VERSION ""

NS_ :

BS_:

BU_: FMS_Gateway
VAL_TABLE_ FMI 0 "Above normal (most severe)" 1 "Below normal (most severe)" 2 "Data erratic" 3 "Voltage above normal" 4 "Voltage below normal" 5 "Current below normal" 6 "Current above normal" 7 "Mechanical system not responding" 8 "Abnormal frequency" 9 "Abnormal update rate" 10 "Abnormal rate of change" 11 "Root cause not known" 12 "Bad intelligent device" 13 "Out of calibration" 14 "Special intstructions" 15 "Above normal (least severe)" 16 "Above normal (moderately severe)" 17 "Below normal (least severe)" 18 "Below normal (moderately severe)" 19 "Received network data in error" 20 "Data drifted high" 21 "Data drifted low" 31 "Condition exists" ;

BO_ 3221225472 VECTOR__INDEPENDENT_SIG_MSG: 0 Vector__XXX
 SG_ NetworkMessageControlByte : 0|8@1+ (1,0) [0|255] "" Vector__XXX

BO_ 2566827774 AIR1: 8 Vector__XXX
 SG_ ServiceBrakeAirPressureCircuit2 : 24|8@1+ (8,0) [0|2040] "kPa" Vector__XXX
 SG_ ServiceBrakeAirPressureCircuit1 : 16|8@1+ (8,0) [0|2040] "kPa" Vector__XXX

BO_ 2565868030 VDC2: 8 Vector__XXX
 SG_ SteeringWheelAngle : 0|16@1+ (0.0009765625,-31.374) [-31.374|31.374] "°" Vector__XXX

BO_ 2566699006 VEP4: 8 Vector__XXX
 SG_ HybridBatteryPackRemainingCharge : 0|16@1+ (0.0025,0) [0|163.6375] "" Vector__XXX

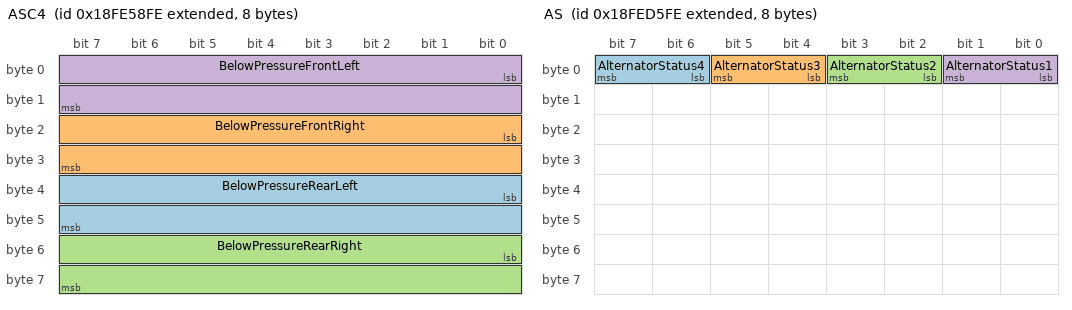
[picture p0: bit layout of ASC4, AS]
BO_ 2566805758 ASC4: 8 Vector__XXX
 SG_ BelowPressureRearLeft : 32|16@1+ (1,0) [0|0] "kPa" Vector__XXX
 SG_ BelowPressureFrontRight : 16|16@1+ (1,0) [0|0] "kPa" Vector__XXX
 SG_ BelowPressureRearRight : 48|16@1+ (1,0) [0|0] "kPa" Vector__XXX
 SG_ BelowPressureFrontLeft : 0|16@1+ (1,0) [0|0] "kPa" Vector__XXX

BO_ 2565867006 ETC2: 8 Vector__XXX
 SG_ SelectedGear : 0|8@1+ (1,-125) [-125|130] "" Vector__XXX
 SG_ CurrentGear : 24|8@1+ (1,-125) [-125|130] "" Vector__XXX

BO_ 2566837758 AS: 8 Vector__XXX
 SG_ AlternatorStatus4 : 6|2@1+ (1,0) [0|3] "" Vector__XXX
 SG_ AlternatorStatus3 : 4|2@1+ (1,0) [0|3] "" Vector__XXX
 SG_ AlternatorStatus2 : 2|2@1+ (1,0) [0|3] "" Vector__XXX
 SG_ AlternatorStatus1 : 0|2@1+ (1,0) [0|3] "" Vector__XXX

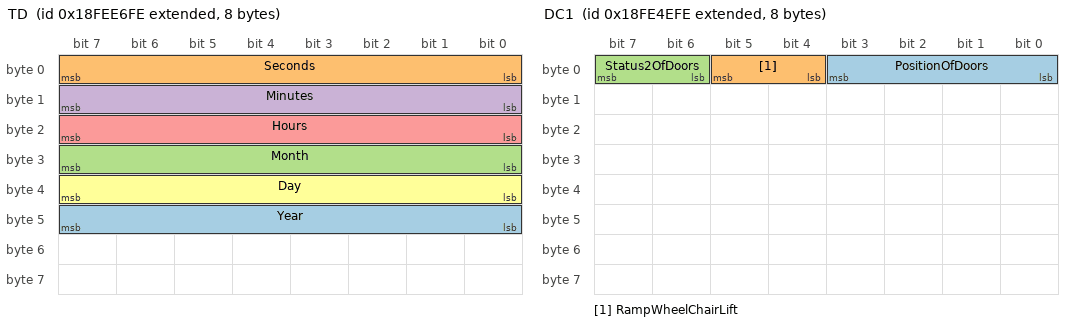
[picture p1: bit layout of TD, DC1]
BO_ 2566842110 TD: 8 Vector__XXX
 SG_ Year : 40|8@1+ (1,1985) [1985|2240] "" Vector__XXX
 SG_ Seconds : 0|8@1+ (0.25,0) [0|59.75] "s" Vector__XXX
 SG_ Month : 24|8@1+ (1,0) [0|11] "" Vector__XXX
 SG_ Minutes : 8|8@1- (1,0) [0|59] "min" Vector__XXX
 SG_ Hours : 16|8@1+ (1,0) [0|23] "" Vector__XXX
 SG_ Day : 32|8@1+ (0.25,0) [0|31] "d" Vector__XXX

BO_ 2566759934 DC2: 8 Vector__XXX
 SG_ EnableStatusDoor9 : 52|2@1+ (1,0) [0|3] "" Vector__XXX
 SG_ EnableStatusDoor8 : 46|2@1+ (1,0) [0|3] "" Vector__XXX
 SG_ EnableStatusDoor7 : 40|2@1+ (1,0) [0|3] "" Vector__XXX
 SG_ EnableStatusDoor6 : 34|2@1+ (1,0) [0|3] "" Vector__XXX
 SG_ EnableStatusDoor5 : 28|2@1+ (1,0) [0|3] "" Vector__XXX
 SG_ EnableStatusDoor4 : 22|2@1+ (1,0) [0|3] "" Vector__XXX
 SG_ EnableStatusDoor3 : 16|2@1+ (1,0) [0|3] "" Vector__XXX
 SG_ EnableStatusDoor2 : 10|2@1+ (1,0) [0|3] "" Vector__XXX
 SG_ EnableStatusDoor10 : 58|2@1+ (1,0) [0|3] "" Vector__XXX
 SG_ EnableStatusDoor1 : 4|2@1+ (1,0) [0|3] "" Vector__XXX
 SG_ OpenStatusDoor9 : 50|2@1+ (1,0) [0|3] "" Vector__XXX
 SG_ OpenStatusDoor8 : 44|2@1+ (1,0) [0|3] "" Vector__XXX
 SG_ OpenStatusDoor7 : 38|2@1+ (1,0) [0|3] "" Vector__XXX
 SG_ OpenStatusDoor6 : 32|2@1+ (1,0) [0|3] "" Vector__XXX
 SG_ OpenStatusDoor5 : 26|2@1+ (1,0) [0|3] "" Vector__XXX
 SG_ OpenStatusDoor4 : 20|2@1+ (1,0) [0|3] "" Vector__XXX
 SG_ OpenStatusDoor3 : 14|2@1+ (1,0) [0|3] "" Vector__XXX
 SG_ OpenStatusDoor2 : 8|2@1+ (1,0) [0|3] "" Vector__XXX
 SG_ OpenStatusDoor10 : 56|2@1+ (1,0) [0|3] "" Vector__XXX
 SG_ OpenStatusDoor1 : 2|2@1+ (1,0) [0|3] "" Vector__XXX
 SG_ LockStatusDoor9 : 48|2@1+ (1,0) [0|0] "" Vector__XXX
 SG_ LockStatusDoor8 : 42|2@1+ (1,0) [0|0] "" Vector__XXX
 SG_ LockStatusDoor7 : 36|2@1+ (1,0) [0|0] "" Vector__XXX
 SG_ LockStatusDoor6 : 30|2@1+ (1,0) [0|0] "" Vector__XXX
 SG_ LockStatusDoor5 : 24|2@1+ (1,0) [0|0] "" Vector__XXX
 SG_ LockStatusDoor4 : 18|2@1+ (1,0) [0|0] "" Vector__XXX
 SG_ LockStatusDoor3 : 12|2@1+ (1,0) [0|0] "" Vector__XXX
 SG_ LockStatusDoor2 : 6|2@1+ (1,0) [0|0] "" Vector__XXX
 SG_ LockStatusDoor10 : 54|2@1+ (1,0) [0|0] "" Vector__XXX
 SG_ LockStatusDoor1 : 0|2@1+ (1,0) [0|0] "" Vector__XXX

BO_ 2566803198 DC1: 8 Vector__XXX
 SG_ PositionOfDoors : 0|4@1+ (1,0) [0|15] "" Vector__XXX
 SG_ RampWheelChairLift : 4|2@1+ (1,0) [0|3] "" Vector__XXX
 SG_ Status2OfDoors : 6|2@1+ (1,0) [0|3] "" Vector__XXX

BO_ 2566811902 CVW: 8 Vector__XXX
 SG_ GrossCombinationVehicleWeigt : 16|16@1+ (10,0) [0|642550] "kg" Vector__XXX

BO_ 2566759678 PTODE: 8 Vector__XXX
 SG_ AtLeastOnePtoEngaged : 48|2@1+ (1,0) [0|3] "" Vector__XXX

BO_ 2566832382 SERV: 8 FMS_Gateway
 SG_ ServiceDistance : 8|16@1+ (5,-160635) [-160635|167040] "km" Vector__XXX

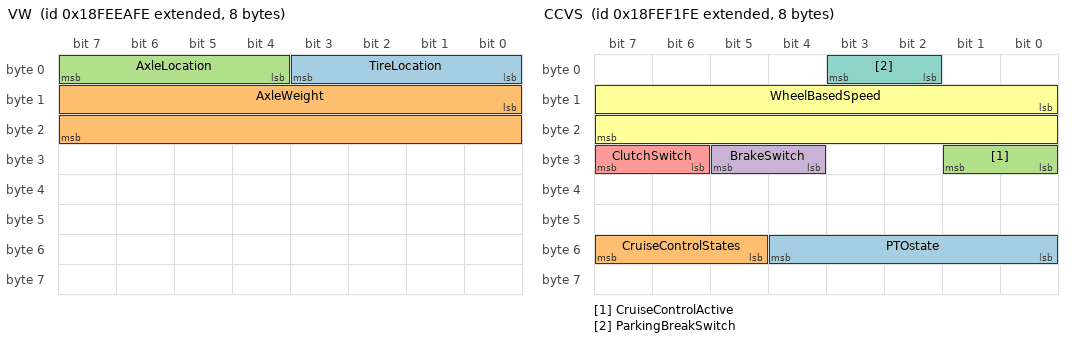
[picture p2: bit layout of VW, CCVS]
BO_ 2566843134 VW: 8 FMS_Gateway
 SG_ TireLocation : 0|4@1+ (1,0) [0|15] "" Vector__XXX
 SG_ AxleWeight : 8|16@1+ (0.5,0) [0|32767.5] "kg" Vector__XXX
 SG_ AxleLocation : 4|4@1+ (1,0) [0|15] "" Vector__XXX

BO_ 2364539902 EEC2: 8 FMS_Gateway
 SG_ EnginePercentLoadAtCurrentSpeed : 16|8@1+ (1,0) [0|125] "%" Vector__XXX
 SG_ AcceleratorPedalPosition1 : 8|8@1+ (0.4,0) [0|100] "%" Vector__XXX

BO_ 2566844926 CCVS: 8 FMS_Gateway
 SG_ PTOstate : 48|5@1+ (1,0) [0|31] "" Vector__XXX
 SG_ CruiseControlStates : 53|3@1+ (1,0) [0|7] "" Vector__XXX
 SG_ CruiseControlActive : 24|2@1+ (1,0) [0|3] "" Vector__XXX
 SG_ BrakeSwitch : 28|2@1+ (1,0) [0|3] "" Vector__XXX
 SG_ ClutchSwitch : 30|2@1+ (1,0) [0|0] "" Vector__XXX
 SG_ WheelBasedSpeed : 8|16@1+ (0.00390625,0) [0|255.99609375] "km/h" Vector__XXX
 SG_ ParkingBreakSwitch : 2|2@1+ (1,0) [0|3] "" Vector__XXX

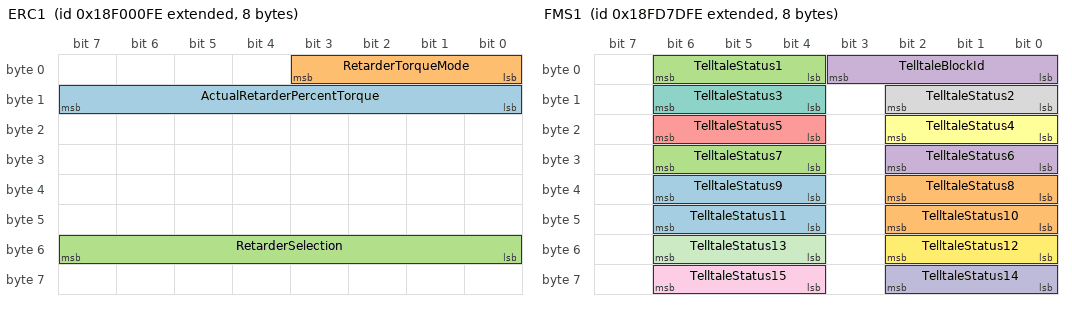
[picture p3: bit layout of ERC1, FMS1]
BO_ 2565865726 ERC1: 8 Vector__XXX
 SG_ ActualRetarderPercentTorque : 8|8@1+ (1,-125) [0|0] "%" Vector__XXX
 SG_ RetarderTorqueMode : 0|4@1+ (1,0) [0|15] "" Vector__XXX
 SG_ RetarderSelection : 48|8@1- (0.4,0) [0|0] "" Vector__XXX

BO_ 2566828030 GFC: 8 Vector__XXX
 SG_ TotalFuelUsed : 32|32@1+ (0.5,0) [0|2105540607.5] "kg" Vector__XXX

BO_ 2566767358 EEC14: 8 Vector__XXX
 SG_ FuelType : 48|8@1+ (1,0) [0|255] "" Vector__XXX

BO_ 2565865982 EBC1: 8 Vector__XXX
 SG_ BrakePedalPosition : 8|8@1+ (0.4,0) [0|100] "%" Vector__XXX

BO_ 2566749694 FMS1: 8 Vector__XXX
 SG_ TelltaleStatus9 : 36|3@1- (1,0) [0|0] "" Vector__XXX
 SG_ TelltaleStatus8 : 32|3@1- (1,0) [0|0] "" Vector__XXX
 SG_ TelltaleStatus7 : 28|3@1- (1,0) [0|0] "" Vector__XXX
 SG_ TelltaleStatus6 : 24|3@1- (1,0) [0|0] "" Vector__XXX
 SG_ TelltaleStatus5 : 20|3@1- (1,0) [0|0] "" Vector__XXX
 SG_ TelltaleStatus4 : 16|3@1- (1,0) [0|0] "" Vector__XXX
 SG_ TelltaleStatus3 : 12|3@1- (1,0) [0|0] "" Vector__XXX
 SG_ TelltaleStatus2 : 8|3@1- (1,0) [0|0] "" Vector__XXX
 SG_ TelltaleStatus15 : 60|3@1- (1,0) [0|0] "" Vector__XXX
 SG_ TelltaleStatus14 : 56|3@1- (1,0) [0|0] "" Vector__XXX
 SG_ TelltaleStatus13 : 52|3@1- (1,0) [0|0] "" Vector__XXX
 SG_ TelltaleStatus12 : 48|3@1- (1,0) [0|0] "" Vector__XXX
 SG_ TelltaleStatus11 : 44|3@1- (1,0) [0|0] "" Vector__XXX
 SG_ TelltaleStatus10 : 40|3@1- (1,0) [0|0] "" Vector__XXX
 SG_ TelltaleStatus1 : 4|3@1- (1,0) [0|0] "" Vector__XXX
 SG_ TelltaleBlockId : 0|4@1+ (1,0) [0|15] "" Vector__XXX

BO_ 2566805246 AT1T1I: 8 Vector__XXX
 SG_ AftertreatmentDieselExhaustFluid : 0|8@1- (0.4,0) [0|100] "%" Vector__XXX

BO_ 2566719998 HRLFC: 8 Vector__XXX
 SG_ HighResEngineTotalFuelUsed : 32|32@1+ (0.001,0) [0|4211081.215] "l" Vector__XXX

BO_ 2566845182 LFE: 8 Vector__XXX
 SG_ InstantaneousFuelEconomy : 16|16@1+ (0.001953125,0) [0|125.5] "km/l" Vector__XXX
 SG_ FuelRate : 0|16@1+ (0.05,0) [0|3212.75] "l/h" Vector__XXX

BO_ 2566810622 DI: 8 Vector__XXX
 SG_ Driver2Identification : 8|8@1+ (1,0) [0|255] "" Vector__XXX
 SG_ Driver1Identification : 0|8@1+ (1,0) [0|255] "" Vector__XXX

BO_ 2566845950 AMB: 8 Vector__XXX
 SG_ AmbientAirTemperature : 24|16@1+ (0.03125,-273) [-273|1774.96875] "" Vector__XXX

BO_ 2566844158 ET1: 8 FMS_Gateway
 SG_ EngineCoolantTemperature : 0|8@1+ (1,-40) [-40|210] "°C" Vector__XXX

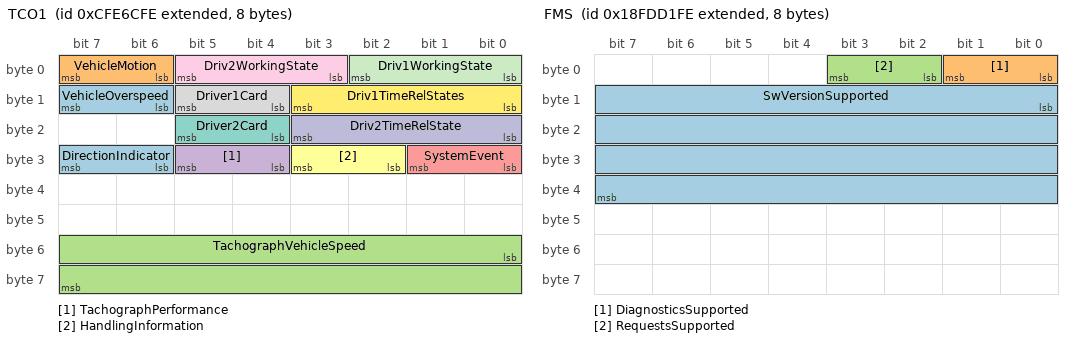
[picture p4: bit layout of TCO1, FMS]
BO_ 2365484286 TCO1: 8 FMS_Gateway
 SG_ VehicleOverspeed : 14|2@1+ (1,0) [0|3] "" Vector__XXX
 SG_ VehicleMotion : 6|2@1+ (1,0) [0|3] "" Vector__XXX
 SG_ TachographVehicleSpeed : 48|16@1+ (0.00390625,0) [0|255.99609375] "" Vector__XXX
 SG_ TachographPerformance : 28|2@1+ (1,0) [0|3] "" Vector__XXX
 SG_ SystemEvent : 24|2@1+ (1,0) [0|3] "" Vector__XXX
 SG_ HandlingInformation : 26|2@1+ (1,0) [0|3] "" Vector__XXX
 SG_ Driver2Card : 20|2@1+ (1,0) [0|3] "" Vector__XXX
 SG_ Driver1Card : 12|2@1+ (1,0) [0|3] "" Vector__XXX
 SG_ Driv2WorkingState : 3|3@1+ (1,0) [0|7] "" Vector__XXX
 SG_ Driv2TimeRelState : 16|4@1+ (1,0) [0|15] "" Vector__XXX
 SG_ Driv1WorkingState : 0|3@1+ (1,0) [0|7] "" Vector__XXX
 SG_ Driv1TimeRelStates : 8|4@1+ (1,0) [0|15] "" Vector__XXX
 SG_ DirectionIndicator : 30|2@1+ (1,0) [0|3] "" Vector__XXX

BO_ 2566832638 VDHR: 8 Vector__XXX
 SG_ HighResTotalVehicleDistance : 0|32@1+ (5,0) [0|21055406000] "m" Vector__XXX

BO_ 2566771198 FMS: 8 Vector__XXX
 SG_ SwVersionSupported : 8|32@1+ (1,0) [0|4294967295] "" Vector__XXX
 SG_ DiagnosticsSupported : 0|2@1+ (1,0) [0|3] "" Vector__XXX
 SG_ RequestsSupported : 2|2@1+ (1,0) [0|3] "" Vector__XXX

BO_ 2566843646 VI: 8 FMS_Gateway
 SG_ VehicleIdentificationNumber : 0|8@1+ (1,0) [0|0] "" Vector__XXX

BO_ 2566841854 HOURS: 8 FMS_Gateway
 SG_ EngineTotalHoursOfOperation : 0|32@1+ (0.05,0) [0|210554060] "h" Vector__XXX

BO_ 2364540158 EEC1: 8 FMS_Gateway
 SG_ EngineSpeed : 24|16@1+ (0.125,0) [0|8031.875] "rpm" Vector__XXX
 SG_ ActualEngine : 16|8@1+ (1,-125) [-125|130] "%" Vector__XXX

BO_ 2566847742 DD1: 8 FMS_Gateway
 SG_ FuelLevel2 : 48|8@1+ (0.4,0) [0|100] "%" Vector__XXX
 SG_ FuelLevel1 : 8|8@1+ (0.4,0) [0|100] "%" Vector__XXX

BO_ 2566842878 LFC: 8 FMS_Gateway
 SG_ EngineTotalFuelUsed : 32|32@1+ (0.5,0) [0|2105540607.5] "l" Vector__XXX

BO_ 2559835902 NM: 8 Vector__XXX
 SG_ ErrorCode m4 : 0|8@1+ (1,0) [0|255] "" Vector__XXX
 SG_ CommandedAAC m0 : 63|1@1+ (1,0) [0|1] "" Vector__XXX
 SG_ CommandedIndustryGroup m0 : 60|3@1+ (1,0) [0|7] "" Vector__XXX
 SG_ CommandedVehicleSystemInstance m0 : 56|4@1+ (1,0) [0|15] "" Vector__XXX
 SG_ CommandedVehicleSystem m0 : 49|7@1+ (1,0) [0|126] "" Vector__XXX
 SG_ CommandedFunction m0 : 40|8@1+ (1,0) [0|254] "" Vector__XXX
 SG_ CommandedFunctionInstance m0 : 35|5@1+ (1,0) [0|31] "" Vector__XXX
 SG_ CommandedECUInstance m0 : 32|3@1+ (1,0) [0|7] "" Vector__XXX
 SG_ CommandedManufacturerCode m0 : 21|11@1+ (1,0) [0|2047] "" Vector__XXX
 SG_ NMControlModeIndicator M : 16|4@1+ (1,0) [0|15] "" Vector__XXX
 SG_ AACQualifierFlag m0 : 15|1@1+ (1,0) [0|1] "" Vector__XXX
 SG_ IndustryGroupQualifierFlag m0 : 14|1@1+ (1,0) [0|1] "" Vector__XXX
 SG_ VehicleSystemInstanceQualifFlag m0 : 13|1@1+ (1,0) [0|1] "" Vector__XXX
 SG_ VehicleSystemQualifierFlag m0 : 12|1@1+ (1,0) [0|1] "" Vector__XXX
 SG_ FunctionQualifierFlag m0 : 11|1@1+ (1,0) [0|1] "" Vector__XXX
 SG_ FunctionInstanceQualifierFlag m0 : 10|1@1+ (1,0) [0|1] "" Vector__XXX
 SG_ ECUInstanceQualifierFlag m0 : 9|1@1+ (1,0) [0|1] "" Vector__XXX
 SG_ ManufacturerCodeQualifierFlag m0 : 8|1@1+ (1,0) [0|1] "" Vector__XXX
 SG_ NAMEChecksum m0 : 0|8@1+ (1,0) [0|255] "" Vector__XXX

BO_ 2566786302 WSMEM: 8 Vector__XXX
 SG_ ReservedBit : 48|1@1+ (1,0) [0|0] "" Vector__XXX
 SG_ VehicleSystem5 m5 : 49|7@1+ (1,0) [0|127] "" Vector__XXX
 SG_ VehicleSystem4 m4 : 49|7@1+ (1,0) [0|127] "" Vector__XXX
 SG_ VehicleSystem3 m3 : 49|7@1+ (1,0) [0|127] "" Vector__XXX
 SG_ VehicleSystem2 m2 : 49|7@1+ (1,0) [0|127] "" Vector__XXX
 SG_ VehicleSystem1 m1 : 49|7@1+ (1,0) [0|127] "" Vector__XXX
 SG_ ArbitraryAddressCapable : 63|1@1+ (1,0) [0|1] "" Vector__XXX
 SG_ IndustryGroup M : 60|3@1+ (1,0) [0|7] "" Vector__XXX
 SG_ VehicleSystemInstance : 56|4@1+ (1,0) [0|15] "" Vector__XXX
 SG_ VehicleSystem m0 : 49|7@1+ (1,0) [0|127] "" Vector__XXX
 SG_ ECUInstance : 32|3@1+ (1,0) [0|7] "" Vector__XXX
 SG_ FunctionInstance : 35|5@1+ (1,0) [0|31] "" Vector__XXX
 SG_ Function : 40|8@1+ (1,0) [0|255] "" Vector__XXX
 SG_ ManufacturerCode : 21|11@1+ (1,0) [0|2047] "" Vector__XXX
 SG_ IdentityNumber : 0|21@1+ (1,0) [0|2097152] "" Vector__XXX

BO_ 2566786558 WSMSTR: 8 Vector__XXX
 SG_ NumberOfMembers : 0|8@1+ (1,0) [0|0] "" Vector__XXX

CM_ "J1939 messages without part -7x";
CM_ BO_ 3221225472 "This is a message for not used signals, created by Vector CANdb++ DBC OLE DB Provider.";
CM_ SG_ 3221225472 NetworkMessageControlByte "Identifies the function or service of an instance of the Network Message.  
A summary of the Network Message Control Bytes value assignments are defined within SAE J1939-31.";
CM_ BO_ 2566827774 " The pneumatic pressure in the service brake circuit or reservoir";
CM_ BO_ 2565868030 "Vehicle Dynamic Stability Control 2";
CM_ BO_ 2566699006 "Vehicle Electrical Power #4";
CM_ BO_ 2566805758 "Air Suspension Control 4";
CM_ BO_ 2565867006 "Electronic Transmission Controller 2";
CM_ BO_ 2566837758 "Alternator Speed";
CM_ BO_ 2566842110 "Time / Date";
CM_ BO_ 2566759934 "Door Control 2";
CM_ BO_ 2566803198 "Door Control 1";
CM_ BO_ 2566811902 "Combination Vehicle Weight";
CM_ SG_ 2566811902 GrossCombinationVehicleWeigt "The total weight of the truck and all attached trailers.";
CM_ BO_ 2566759678 "PTO Drive Engagement";
CM_ BO_ 2566832382 "Service Information";
CM_ BO_ 2566843134 "Vehicle Weight";
CM_ SG_ 2566843134 TireLocation "Tire location Bit-mapped counting left to right facing forward";
CM_ SG_ 2566843134 AxleLocation "Axle location Bit-mapped position number counting front to back facing forward";
CM_ BO_ 2364539902 "Electronic Engine Controller #2";
CM_ BO_ 2566844926 "Cruise Control/Vehicle Speed 1";
CM_ BO_ 2565865726 "Electronic Retarder Controller 1";
CM_ SG_ 2565865726 RetarderSelection "Retarder Selection, non-engine";
CM_ BO_ 2566828030 "Fuel Consumption (Gaseous): Total fuel consumed over the life of the engine.";
CM_ BO_ 2566767358 "Electronic Engine Controller 14: Type of fuel currently being utilized by the vehicle";
CM_ BO_ 2565865982 "Electronic Brake Controller 1";
CM_ BO_ 2566749694 "FMS Tell Tale Status";
CM_ BO_ 2566805246 "Aftertreatment 1 Diesel Exhaust Fluid Tank 1 Information";
CM_ SG_ 2566805246 AftertreatmentDieselExhaustFluid "Ratio of volume of diesel exhaust fluid to the total volume of diesel exhaust fluid storage container.";
CM_ BO_ 2566719998 "High Resolution Fuel Consumption (Liquid):";
CM_ BO_ 2566845182 "Fuel Economy: Amount of fuel consumed by engine per unit of time
Instantaneous Fuel Economy: Current fuel economy at current vehicle velocity";
CM_ SG_ 2566845182 FuelRate "Fuel rate: Amount of fuel consumed by engine per unit of time";
CM_ BO_ 2566810622 "Driver Identification. ASCII '*' delimiter separates first and second driver";
CM_ BO_ 2566845950 "Ambient Air Temperature: Temperature of air surrounding vehicle.";
CM_ SG_ 2566845950 AmbientAirTemperature "Ambient Air Temperature
0.03125 °C / Bit gain
- 273 °C offset";
CM_ BO_ 2566844158 "Engine Temperature 1: Temperature of liquid found in engine cooling system.";
CM_ BO_ 2365484286 "Tachograph";
CM_ BO_ 2566832638 "High Resolution Vehicle Distance: Accumulated distance travelled by the vehicle during its operation";
CM_ BO_ 2566771198 "FMS-standard Interface Identity / Capabilities";
CM_ SG_ 2566771198 SwVersionSupported "SW-version supported Version number in the format ab.cd where the first byte represents “a”
ASCII";
CM_ BO_ 2566843646 "Vehicle Identification Number (VIN) as assigned by the vehicle manufacturer";
CM_ BO_ 2566841854 "Engine Hours, Revolutions: Accumulated time of operation of engine.";
CM_ BO_ 2364540158 "Electronic Engine Controller #1. The calculated output torque of the engine.";
CM_ BO_ 2566847742 "Dash Display 1";
CM_ SG_ 2566847742 FuelLevel2 "Fuel Level 2 is only used if different fuel types in different storage container";
CM_ SG_ 2566847742 FuelLevel1 "Ratio of volume of fuel to the total volume of fuel storage container.";
CM_ BO_ 2566842878 "Fuel Consumption: Accumulated amount of fuel used during vehicle operation.";
CM_ SG_ 2566842878 EngineTotalFuelUsed "SPN 250";
CM_ BO_ 2559835902 "NAME Management Message
A message to change fields of the NAME of a CA";
CM_ SG_ 2559835902 ErrorCode "When  the  NM Control Mode Indicator is set to Mode 0 “Set Pending NAME”, NAME checksum is used as a check to ensure the NM message has been sent to the correct CA.";
CM_ SG_ 2559835902 CommandedAAC "When the NM Control Mode Indicator is set to Mode 0 – Set Pending NAME and the Arbitrary Address Capable Qualifier Flag (SPN 5665) is set to “0”";
CM_ SG_ 2559835902 CommandedIndustryGroup "When the NM Control Mode Indicator is set to Mode 0 – Set Pending NAME and the Industry Group Qualifier Flag (SPN 5664) is set to “0”";
CM_ SG_ 2559835902 CommandedVehicleSystemInstance "When the NM Control Mode Indicator is set to Mode 0 – Set Pending NAME and the Vehicle System Instance Qualifier Flag (SPN 5663) is set to “0”";
CM_ SG_ 2559835902 CommandedVehicleSystem "When the NM Control Mode Indicator is set to Mode 0 – Set Pending NAME and the Vehicle System Qualifier Flag (SPN 5662) is set to “0”";
CM_ SG_ 2559835902 CommandedFunction "When the NM Control Mode Indicator is set to Mode 0 – Set Pending NAME and the Function Qualifier Flag (SPN 5661) is set to “0”";
CM_ SG_ 2559835902 CommandedFunctionInstance "When the NM Control Mode Indicator is set to Mode 0 – Set Pending NAME and the Function Instance Qualifier Flag (SPN 5660) is set to “0”";
CM_ SG_ 2559835902 CommandedECUInstance "When the NM Control Mode Indicator is set to Mode 0 – Set Pending NAME and the ECU Instance Qualifier Flag (SPN 5659) is set to “0”";
CM_ SG_ 2559835902 CommandedManufacturerCode "When the NM Control Mode Indicator is set to Mode 0 – Set Pending NAME and the Manufacturer Code Qualifier Flag (SPN 5658) is set to “0”";
CM_ SG_ 2559835902 NMControlModeIndicator "This four bit parameter is used to define the purpose of the NM message.";
CM_ SG_ 2559835902 AACQualifierFlag "When the NM Control Mode Indicator is set to Mode 0 – Set Pending NAME, this qualifier flag is used to indicate whether the Arbitrary Address Capable field (SPN  5674) shall be used";
CM_ SG_ 2559835902 IndustryGroupQualifierFlag "When the NM Control Mode Indicator is set to Mode 0 – Set Pending NAME, this qualifier flag is used to indicate whether the Industry Group field (SPN 5673) shall be used";
CM_ SG_ 2559835902 VehicleSystemInstanceQualifFlag "When the NM Control Mode Indicator is set to Mode 0 – Set Pending NAME, this qualifier flag is used to indicate whether the Vehicle System Instance field (SPN 5672) shall be used ";
CM_ SG_ 2559835902 VehicleSystemQualifierFlag "When the NM Control Mode Indicator is set to Mode 0 – Set Pending NAME, this qualifier flag is used to indicate whether the Vehicle System field (SPN 5671) shall be used";
CM_ SG_ 2559835902 FunctionQualifierFlag "When the NM Control Mode Indicator is set to Mode 0 – Set Pending NAME, this qualifier flag is used to indicate whether the Function field (SPN 5670) shall be used";
CM_ SG_ 2559835902 FunctionInstanceQualifierFlag "When the NM Control Mode Indicator is set to Mode 0 – Set Pending NAME, this qualifier flag is used to indicate whether the Function Instance field (SPN 5669) shall be used";
CM_ SG_ 2559835902 ECUInstanceQualifierFlag "When the NM Control Mode Indicator is set to Mode 0 – Set Pending NAME, this qualifier flag is used to indicate whether the ECU Instance field (SPN 5668) shall be used";
CM_ SG_ 2559835902 ManufacturerCodeQualifierFlag "When the NM Control Mode Indicator is set to Mode 0 – Set Pending NAME, this qualifier flag is used to indicate whether the Commanded Manufacturer Code field (SPN 5667) shall be used";
CM_ SG_ 2559835902 NAMEChecksum "When  the  NM Control Mode Indicator is set to Mode 0 “Set Pending NAME”, NAME checksum is used as a check to ensure the NM message has been sent to the correct CA.";
CM_ BO_ 2566786302 "Working Set Member
This message is sent by the Master of a Working Set to identify an individual member of a specific Working Set (Master’s Source Address identifies the particular Working Set).";
CM_ SG_ 2566786302 IndustryGroup "0 = Global; 
   1  = On-Highway; 
   2  = Agricultural and Forestry; 
   3  = Construction; 
   4  = Marine;
   5  = Industrial - Process
          Control - Stationary (Gen-Sets)
   6  = Reserve for SAE
   7  = Reserve for SAE";
CM_ SG_ 2566786302 ManufacturerCode "Assigned by NMEA 2000 Committee";
CM_ BO_ 2566786558 "Working Set Master
This message is sent by the Master of a Working Set to identify how many members there are in said set.";
BA_DEF_ SG_  "SigType" ENUM  "Default","Range","RangeSigned","ASCII","Discrete","Control","ReferencePGN","DTC","StringDelimiter","StringLength","StringLengthControl","MessageCounter","MessageChecksum";
BA_DEF_ SG_  "GenSigStartValue" INT 0 2147483647;
BA_DEF_ SG_  "GenSigSendType" ENUM  "Cyclic","OnWrite","OnWriteWithRepetition","OnChange","OnChangeWithRepetition","IfActive","IfActiveWithRepetition","NoSigSendType";
BA_DEF_ SG_  "GenSigILSupport" ENUM  "No","Yes";
BA_DEF_ SG_  "GenSigEVName" STRING ;
BA_DEF_ SG_  "SPN" INT 0 524287;
BA_DEF_ BO_  "GenMsgILSupport" ENUM  "No","Yes";
BA_DEF_ BO_  "GenMsgRequestable" INT 0 1;
BA_DEF_ BO_  "GenMsgSendType" ENUM  "cyclic","NotUsed","NotUsed","NotUsed","NotUsed","NotUsed","NotUsed","IfActive","noMsgSendType";
BA_DEF_ BO_  "VFrameFormat" ENUM  "StandardCAN","ExtendedCAN","reserved","J1939PG";
BA_DEF_ BO_  "GenMsgCycleTime" INT 0 3600000;
BA_DEF_ BU_  "NodeLayerModules" STRING ;
BA_DEF_ BU_  "NmStationAddress" INT 0 255;
BA_DEF_ BU_  "NmJ1939AAC" INT 0 1;
BA_DEF_ BU_  "NmJ1939Function" INT 0 255;
BA_DEF_ BU_  "NmJ1939ManufacturerCode" INT 0 2047;
BA_DEF_  "SAE_J1939_DA_SpecVersion" STRING ;
BA_DEF_  "SAE_J1939_81_SpecVersion" STRING ;
BA_DEF_  "DatabaseVersion" STRING ;
BA_DEF_  "BusType" STRING ;
BA_DEF_  "ProtocolType" STRING ;
BA_DEF_  "SAE_J1939_21_SpecVersion" STRING ;
BA_DEF_DEF_  "SigType" "Default";
BA_DEF_DEF_  "GenSigStartValue" 0;
BA_DEF_DEF_  "GenSigSendType" "NoSigSendType";
BA_DEF_DEF_  "GenSigILSupport" "Yes";
BA_DEF_DEF_  "GenSigEVName" "Env@Nodename_@Signame";
BA_DEF_DEF_  "SPN" 0;
BA_DEF_DEF_  "GenMsgILSupport" "Yes";
BA_DEF_DEF_  "GenMsgRequestable" 1;
BA_DEF_DEF_  "GenMsgSendType" "noMsgSendType";
BA_DEF_DEF_  "VFrameFormat" "J1939PG";
BA_DEF_DEF_  "GenMsgCycleTime" 0;
BA_DEF_DEF_  "NodeLayerModules" "";
BA_DEF_DEF_  "NmStationAddress" 254;
BA_DEF_DEF_  "NmJ1939AAC" 0;
BA_DEF_DEF_  "NmJ1939Function" 0;
BA_DEF_DEF_  "NmJ1939ManufacturerCode" 0;
BA_DEF_DEF_  "SAE_J1939_DA_SpecVersion" "";
BA_DEF_DEF_  "SAE_J1939_81_SpecVersion" "";
BA_DEF_DEF_  "DatabaseVersion" "";
BA_DEF_DEF_  "BusType" "";
BA_DEF_DEF_  "ProtocolType" "";
BA_DEF_DEF_  "SAE_J1939_21_SpecVersion" "";
BA_ "SAE_J1939_21_SpecVersion" "2018-10";
BA_ "ProtocolType" "J1939";
BA_ "BusType" "CAN";
BA_ "DatabaseVersion" "13.0";
BA_ "SAE_J1939_81_SpecVersion" "2017-03";
BA_ "SAE_J1939_DA_SpecVersion" "2020-01";
BA_ "NodeLayerModules" BU_ FMS_Gateway "J1939_IL.vmodule";
BA_ "NmJ1939ManufacturerCode" BU_ FMS_Gateway 1861;
BA_ "NmJ1939Function" BU_ FMS_Gateway 28;
BA_ "NmStationAddress" BU_ FMS_Gateway 251;
BA_ "GenMsgSendType" BO_ 2566827774 0;
BA_ "GenMsgCycleTime" BO_ 2566827774 1000;
BA_ "GenMsgSendType" BO_ 2565868030 0;
BA_ "GenMsgCycleTime" BO_ 2565868030 100;
BA_ "GenMsgSendType" BO_ 2566699006 0;
BA_ "GenMsgCycleTime" BO_ 2566699006 10000;
BA_ "GenMsgSendType" BO_ 2566805758 0;
BA_ "GenMsgCycleTime" BO_ 2566805758 100;
BA_ "GenMsgSendType" BO_ 2565867006 0;
BA_ "GenMsgCycleTime" BO_ 2565867006 100;
BA_ "GenMsgSendType" BO_ 2566837758 0;
BA_ "GenMsgCycleTime" BO_ 2566837758 1000;
BA_ "GenMsgSendType" BO_ 2566842110 0;
BA_ "GenMsgCycleTime" BO_ 2566842110 1000;
BA_ "GenMsgSendType" BO_ 2566803198 0;
BA_ "GenMsgCycleTime" BO_ 2566803198 100;
BA_ "GenMsgSendType" BO_ 2566811902 0;
BA_ "GenMsgCycleTime" BO_ 2566811902 10000;
BA_ "GenMsgSendType" BO_ 2566759678 0;
BA_ "GenMsgCycleTime" BO_ 2566759678 100;
BA_ "GenMsgSendType" BO_ 2566832382 0;
BA_ "GenMsgCycleTime" BO_ 2566832382 1000;
BA_ "GenMsgSendType" BO_ 2566843134 0;
BA_ "GenMsgCycleTime" BO_ 2566843134 1000;
BA_ "GenMsgSendType" BO_ 2364539902 0;
BA_ "GenMsgCycleTime" BO_ 2364539902 50;
BA_ "GenMsgSendType" BO_ 2566844926 0;
BA_ "GenMsgCycleTime" BO_ 2566844926 100;
BA_ "GenMsgSendType" BO_ 2565865726 0;
BA_ "GenMsgCycleTime" BO_ 2565865726 100;
BA_ "GenMsgSendType" BO_ 2566828030 0;
BA_ "GenMsgCycleTime" BO_ 2566828030 1000;
BA_ "GenMsgSendType" BO_ 2566767358 0;
BA_ "GenMsgCycleTime" BO_ 2566767358 10000;
BA_ "GenMsgSendType" BO_ 2565865982 0;
BA_ "GenMsgCycleTime" BO_ 2565865982 100;
BA_ "GenMsgSendType" BO_ 2566749694 0;
BA_ "GenMsgCycleTime" BO_ 2566749694 1000;
BA_ "GenMsgSendType" BO_ 2566805246 0;
BA_ "GenMsgCycleTime" BO_ 2566805246 1000;
BA_ "GenMsgSendType" BO_ 2566719998 0;
BA_ "GenMsgCycleTime" BO_ 2566719998 1000;
BA_ "GenMsgSendType" BO_ 2566845182 0;
BA_ "GenMsgCycleTime" BO_ 2566845182 100;
BA_ "GenMsgSendType" BO_ 2566810622 0;
BA_ "GenMsgCycleTime" BO_ 2566810622 10000;
BA_ "GenMsgSendType" BO_ 2566845950 0;
BA_ "GenMsgCycleTime" BO_ 2566845950 1000;
BA_ "GenMsgSendType" BO_ 2566844158 0;
BA_ "GenMsgCycleTime" BO_ 2566844158 1000;
BA_ "GenMsgSendType" BO_ 2365484286 0;
BA_ "GenMsgCycleTime" BO_ 2365484286 50;
BA_ "GenMsgSendType" BO_ 2566832638 0;
BA_ "GenMsgCycleTime" BO_ 2566832638 1000;
BA_ "GenMsgSendType" BO_ 2566771198 0;
BA_ "GenMsgCycleTime" BO_ 2566771198 10000;
BA_ "GenMsgSendType" BO_ 2566843646 0;
BA_ "GenMsgCycleTime" BO_ 2566843646 10000;
BA_ "GenMsgSendType" BO_ 2566841854 0;
BA_ "GenMsgCycleTime" BO_ 2566841854 1000;
BA_ "GenMsgSendType" BO_ 2364540158 0;
BA_ "GenMsgCycleTime" BO_ 2364540158 20;
BA_ "GenMsgSendType" BO_ 2566847742 0;
BA_ "GenMsgCycleTime" BO_ 2566847742 1000;
BA_ "GenMsgSendType" BO_ 2566842878 0;
BA_ "GenMsgCycleTime" BO_ 2566842878 1000;
BA_ "SPN" SG_ 3221225472 NetworkMessageControlByte 5592;
BA_ "SigType" SG_ 3221225472 NetworkMessageControlByte 1;
BA_ "SPN" SG_ 2566827774 ServiceBrakeAirPressureCircuit2 1088;
BA_ "SPN" SG_ 2566827774 ServiceBrakeAirPressureCircuit1 1087;
BA_ "GenSigStartValue" SG_ 2565868030 SteeringWheelAngle 32127;
BA_ "SPN" SG_ 2565868030 SteeringWheelAngle 1807;
BA_ "SPN" SG_ 2566699006 HybridBatteryPackRemainingCharge 5464;
BA_ "SPN" SG_ 2566805758 BelowPressureRearLeft 1727;
BA_ "SPN" SG_ 2566805758 BelowPressureFrontRight 1726;
BA_ "SPN" SG_ 2566805758 BelowPressureRearRight 1726;
BA_ "SPN" SG_ 2566805758 BelowPressureFrontLeft 1725;
BA_ "GenSigStartValue" SG_ 2565867006 SelectedGear 125;
BA_ "SPN" SG_ 2565867006 SelectedGear 524;
BA_ "GenSigStartValue" SG_ 2565867006 CurrentGear 125;
BA_ "SPN" SG_ 2565867006 CurrentGear 523;
BA_ "SPN" SG_ 2566837758 AlternatorStatus4 3356;
BA_ "SPN" SG_ 2566837758 AlternatorStatus3 3355;
BA_ "SPN" SG_ 2566837758 AlternatorStatus2 3354;
BA_ "SPN" SG_ 2566837758 AlternatorStatus1 3353;
BA_ "SPN" SG_ 2566842110 Year 964;
BA_ "SPN" SG_ 2566842110 Seconds 959;
BA_ "SPN" SG_ 2566842110 Month 963;
BA_ "SPN" SG_ 2566842110 Minutes 960;
BA_ "SPN" SG_ 2566842110 Hours 961;
BA_ "SPN" SG_ 2566842110 Day 962;
BA_ "SPN" SG_ 2566759934 EnableStatusDoor9 3438;
BA_ "SPN" SG_ 2566759934 EnableStatusDoor8 3435;
BA_ "SPN" SG_ 2566759934 EnableStatusDoor7 3432;
BA_ "SPN" SG_ 2566759934 EnableStatusDoor6 3429;
BA_ "SPN" SG_ 2566759934 EnableStatusDoor5 3426;
BA_ "SPN" SG_ 2566759934 EnableStatusDoor4 3423;
BA_ "SPN" SG_ 2566759934 EnableStatusDoor3 3420;
BA_ "SPN" SG_ 2566759934 EnableStatusDoor2 3417;
BA_ "SPN" SG_ 2566759934 EnableStatusDoor10 3441;
BA_ "SPN" SG_ 2566759934 EnableStatusDoor1 3414;
BA_ "SPN" SG_ 2566759934 OpenStatusDoor9 3437;
BA_ "SPN" SG_ 2566759934 OpenStatusDoor8 3434;
BA_ "SPN" SG_ 2566759934 OpenStatusDoor7 3431;
BA_ "SPN" SG_ 2566759934 OpenStatusDoor6 3428;
BA_ "SPN" SG_ 2566759934 OpenStatusDoor5 3425;
BA_ "SPN" SG_ 2566759934 OpenStatusDoor4 3422;
BA_ "SPN" SG_ 2566759934 OpenStatusDoor3 3419;
BA_ "SPN" SG_ 2566759934 OpenStatusDoor2 3416;
BA_ "SPN" SG_ 2566759934 OpenStatusDoor10 3440;
BA_ "SPN" SG_ 2566759934 OpenStatusDoor1 3413;
BA_ "SPN" SG_ 2566759934 LockStatusDoor9 3436;
BA_ "SPN" SG_ 2566759934 LockStatusDoor8 3433;
BA_ "SPN" SG_ 2566759934 LockStatusDoor7 3430;
BA_ "SPN" SG_ 2566759934 LockStatusDoor6 3427;
BA_ "SPN" SG_ 2566759934 LockStatusDoor5 3424;
BA_ "SPN" SG_ 2566759934 LockStatusDoor4 3421;
BA_ "SPN" SG_ 2566759934 LockStatusDoor3 3418;
BA_ "SPN" SG_ 2566759934 LockStatusDoor2 3415;
BA_ "SPN" SG_ 2566759934 LockStatusDoor10 3439;
BA_ "SPN" SG_ 2566759934 LockStatusDoor1 3412;
BA_ "SPN" SG_ 2566803198 Status2OfDoors 3411;
BA_ "SPN" SG_ 2566811902 GrossCombinationVehicleWeigt 1760;
BA_ "SPN" SG_ 2566759678 AtLeastOnePtoEngaged 3948;
BA_ "GenSigStartValue" SG_ 2566832382 ServiceDistance 32127;
BA_ "SPN" SG_ 2566832382 ServiceDistance 914;
BA_ "SPN" SG_ 2566843134 TireLocation 928;
BA_ "SPN" SG_ 2566843134 AxleWeight 582;
BA_ "SPN" SG_ 2566843134 AxleLocation 928;
BA_ "SPN" SG_ 2364539902 EnginePercentLoadAtCurrentSpeed 92;
BA_ "SPN" SG_ 2364539902 AcceleratorPedalPosition1 91;
BA_ "SPN" SG_ 2566844926 CruiseControlStates 527;
BA_ "SPN" SG_ 2566844926 BrakeSwitch 597;
BA_ "SPN" SG_ 2566844926 ClutchSwitch 598;
BA_ "SPN" SG_ 2566844926 WheelBasedSpeed 84;
BA_ "SPN" SG_ 2566844926 ParkingBreakSwitch 70;
BA_ "GenSigStartValue" SG_ 2565865726 ActualRetarderPercentTorque 125;
BA_ "SPN" SG_ 2565865726 ActualRetarderPercentTorque 520;
BA_ "SPN" SG_ 2565865726 RetarderTorqueMode 900;
BA_ "SPN" SG_ 2565865726 RetarderSelection 1716;
BA_ "SPN" SG_ 2566828030 TotalFuelUsed 1040;
BA_ "SPN" SG_ 2566767358 FuelType 5837;
BA_ "SPN" SG_ 2565865982 BrakePedalPosition 521;
BA_ "SPN" SG_ 2566805246 AftertreatmentDieselExhaustFluid 1761;
BA_ "SPN" SG_ 2566719998 HighResEngineTotalFuelUsed 5054;
BA_ "SPN" SG_ 2566845182 InstantaneousFuelEconomy 184;
BA_ "SPN" SG_ 2566845182 FuelRate 183;
BA_ "SPN" SG_ 2566810622 Driver2Identification 1626;
BA_ "SPN" SG_ 2566810622 Driver1Identification 1625;
BA_ "GenSigStartValue" SG_ 2566845950 AmbientAirTemperature 8736;
BA_ "SPN" SG_ 2566845950 AmbientAirTemperature 171;
BA_ "GenSigStartValue" SG_ 2566844158 EngineCoolantTemperature 40;
BA_ "SPN" SG_ 2566844158 EngineCoolantTemperature 110;
BA_ "SPN" SG_ 2365484286 VehicleOverspeed 1614;
BA_ "SPN" SG_ 2365484286 VehicleMotion 1611;
BA_ "SPN" SG_ 2365484286 TachographPerformance 1620;
BA_ "SPN" SG_ 2365484286 SystemEvent 1622;
BA_ "SPN" SG_ 2365484286 HandlingInformation 1621;
BA_ "SPN" SG_ 2365484286 Driver2Card 1616;
BA_ "SPN" SG_ 2365484286 Driver1Card 1615;
BA_ "SPN" SG_ 2365484286 Driv2WorkingState 1613;
BA_ "SPN" SG_ 2365484286 Driv2TimeRelState 1618;
BA_ "SPN" SG_ 2365484286 Driv1WorkingState 1612;
BA_ "SPN" SG_ 2365484286 Driv1TimeRelStates 1617;
BA_ "SPN" SG_ 2365484286 DirectionIndicator 1619;
BA_ "SPN" SG_ 2566832638 HighResTotalVehicleDistance 917;
BA_ "SPN" SG_ 2566771198 SwVersionSupported 2806;
BA_ "SPN" SG_ 2566771198 DiagnosticsSupported 2804;
BA_ "SPN" SG_ 2566771198 RequestsSupported 2805;
BA_ "SPN" SG_ 2566841854 EngineTotalHoursOfOperation 247;
BA_ "SPN" SG_ 2364540158 EngineSpeed 190;
BA_ "GenSigStartValue" SG_ 2364540158 ActualEngine 125;
BA_ "SPN" SG_ 2364540158 ActualEngine 513;
BA_ "SPN" SG_ 2566847742 FuelLevel2 38;
BA_ "SPN" SG_ 2566847742 FuelLevel1 96;
BA_ "SPN" SG_ 2566842878 EngineTotalFuelUsed 250;
BA_ "SPN" SG_ 2559835902 ErrorCode 5657;
BA_ "SPN" SG_ 2559835902 CommandedAAC 5674;
BA_ "SPN" SG_ 2559835902 CommandedIndustryGroup 5673;
BA_ "SPN" SG_ 2559835902 CommandedVehicleSystemInstance 5672;
BA_ "SPN" SG_ 2559835902 CommandedVehicleSystem 5671;
BA_ "SPN" SG_ 2559835902 CommandedFunction 5670;
BA_ "SPN" SG_ 2559835902 CommandedFunctionInstance 5669;
BA_ "SPN" SG_ 2559835902 CommandedECUInstance 5668;
BA_ "SPN" SG_ 2559835902 CommandedManufacturerCode 5667;
BA_ "SPN" SG_ 2559835902 NMControlModeIndicator 5666;
BA_ "SPN" SG_ 2559835902 AACQualifierFlag 5665;
BA_ "SPN" SG_ 2559835902 IndustryGroupQualifierFlag 5664;
BA_ "SPN" SG_ 2559835902 VehicleSystemInstanceQualifFlag 5663;
BA_ "SPN" SG_ 2559835902 VehicleSystemQualifierFlag 5662;
BA_ "SPN" SG_ 2559835902 FunctionQualifierFlag 5661;
BA_ "SPN" SG_ 2559835902 FunctionInstanceQualifierFlag 5660;
BA_ "SPN" SG_ 2559835902 ECUInstanceQualifierFlag 5659;
BA_ "SPN" SG_ 2559835902 ManufacturerCodeQualifierFlag 5658;
BA_ "SPN" SG_ 2566786302 ArbitraryAddressCapable 2844;
BA_ "SPN" SG_ 2566786302 IndustryGroup 2846;
BA_ "SPN" SG_ 2566786302 VehicleSystemInstance 2843;
BA_ "SPN" SG_ 2566786302 ECUInstance 2840;
BA_ "SPN" SG_ 2566786302 FunctionInstance 2839;
BA_ "SPN" SG_ 2566786302 Function 2841;
BA_ "SPN" SG_ 2566786302 ManufacturerCode 2838;
BA_ "SigType" SG_ 2566786302 ManufacturerCode 1;
BA_ "SPN" SG_ 2566786302 IdentityNumber 2837;
BA_ "SigType" SG_ 2566786558 NumberOfMembers 3;
VAL_ 3221225472 NetworkMessageControlByte 133 "SP_Reset Message " 132 "SP_Response Message " 131 "SP_Request Message " 130 "GP_Reset Message " 129 "GP_Response " 128 "GP_Request " 67 "NTX_Response " 66 "NTX_Request " 65 "NT_Response" 64 "NT_Request " 6 "MFDB_CreateEntry" 5 "MFDB_SetMode" 4 "MFDB_Clear" 3 "MFDB_Delete" 2 "MFDB_Add" 1 "MFDB_Response" 0 "MFDB_Request" ;
VAL_ 2566837758 AlternatorStatus4 3 "not available" 2 "error" 1 "charging" 0 "not charging" ;
VAL_ 2566837758 AlternatorStatus3 3 "not available" 2 "error" 1 "charging" 0 "not charging" ;
VAL_ 2566837758 AlternatorStatus2 3 "not available" 2 "error" 1 "charging" 0 "not charging" ;
VAL_ 2566837758 AlternatorStatus1 3 "not available" 2 "error" 1 "charging" 0 "not charging" ;
VAL_ 2566759934 EnableStatusDoor9 3 "Not available" 2 "Error" 1 "Enabled" 0 "Disabled" ;
VAL_ 2566759934 EnableStatusDoor8 3 "Not available" 2 "Error" 1 "Enabled" 0 "Disabled" ;
VAL_ 2566759934 EnableStatusDoor7 3 "Not available" 2 "Error" 1 "Enabled" 0 "Disabled" ;
VAL_ 2566759934 EnableStatusDoor6 3 "Not available" 2 "Error" 1 "Enabled" 0 "Disabled" ;
VAL_ 2566759934 EnableStatusDoor5 3 "Not available" 2 "Error" 1 "Enabled" 0 "Disabled" ;
VAL_ 2566759934 EnableStatusDoor4 3 "Not available" 2 "Error" 1 "Enabled" 0 "Disabled" ;
VAL_ 2566759934 EnableStatusDoor3 3 "Not available" 2 "Error" 1 "Enabled" 0 "Disabled" ;
VAL_ 2566759934 EnableStatusDoor2 3 "Not available" 2 "Error" 1 "Enabled" 0 "Disabled" ;
VAL_ 2566759934 EnableStatusDoor10 3 "Not available" 2 "Error" 1 "Enabled" 0 "Disabled" ;
VAL_ 2566759934 EnableStatusDoor1 3 "Not available" 2 "Error" 1 "Enabled" 0 "Disabled" ;
VAL_ 2566759934 OpenStatusDoor9 3 "Not available" 2 "Error" 1 "Open" 0 "Closed" ;
VAL_ 2566759934 OpenStatusDoor8 3 "Not available" 2 "Error" 1 "Open" 0 "Closed" ;
VAL_ 2566759934 OpenStatusDoor7 3 "Not available" 2 "Error" 1 "Open" 0 "Closed" ;
VAL_ 2566759934 OpenStatusDoor6 3 "Not available" 2 "Error" 1 "Open" 0 "Closed" ;
VAL_ 2566759934 OpenStatusDoor5 3 "Not available" 2 "Error" 1 "Open" 0 "Closed" ;
VAL_ 2566759934 OpenStatusDoor4 3 "Not available" 2 "Error" 1 "Open" 0 "Closed" ;
VAL_ 2566759934 OpenStatusDoor3 3 "Not available" 2 "Error" 1 "Open" 0 "Closed" ;
VAL_ 2566759934 OpenStatusDoor2 3 "Not available" 2 "Error" 1 "Open" 0 "Closed" ;
VAL_ 2566759934 OpenStatusDoor10 3 "Not available" 2 "Error" 1 "Open" 0 "Closed" ;
VAL_ 2566759934 OpenStatusDoor1 3 "Not available" 2 "Error" 1 "Open" 0 "Closed" ;
VAL_ 2566759934 LockStatusDoor9 3 "Not available" 2 "Error" 1 "Locked" 0 "Unlocked" ;
VAL_ 2566759934 LockStatusDoor8 3 "Not available" 2 "Error" 1 "Locked" 0 "Unlocked" ;
VAL_ 2566759934 LockStatusDoor7 3 "Not available" 2 "Error" 1 "Locked" 0 "Unlocked" ;
VAL_ 2566759934 LockStatusDoor6 3 "Not available" 2 "Error" 1 "Locked" 0 "Unlocked" ;
VAL_ 2566759934 LockStatusDoor5 3 "Not available" 2 "Error" 1 "Locked" 0 "Unlocked" ;
VAL_ 2566759934 LockStatusDoor4 3 "Not available" 2 "Error" 1 "Locked" 0 "Unlocked" ;
VAL_ 2566759934 LockStatusDoor3 3 "Not available" 2 "Error" 1 "Locked" 0 "Unlocked" ;
VAL_ 2566759934 LockStatusDoor2 3 "Not available" 2 "Error" 1 "Locked" 0 "Unlocked" ;
VAL_ 2566759934 LockStatusDoor10 3 "Not available" 2 "Error" 1 "Locked" 0 "Unlocked" ;
VAL_ 2566759934 LockStatusDoor1 3 "Not available" 2 "Error" 1 "Locked" 0 "Unlocked" ;
VAL_ 2566803198 PositionOfDoors 21 "not available" 20 "Error" 2 "all doors closed" 1 "closing last door" 0 "at least one door open" ;
VAL_ 2566803198 RampWheelChairLift 3 "not available" 2 "Error" 1 "outside bus" 0 "inside bus" ;
VAL_ 2566803198 Status2OfDoors 3 "not available" 2 "error" 1 "at least one door enabled" 0 "all bus doors disabled" ;
VAL_ 2566759678 AtLeastOnePtoEngaged 3 "Not available" 2 "Error" 1 "At least one PTO drive engaged" 0 "No PTO drive is engaged" ;
VAL_ 2566844926 PTOstate 49 "not available" 5 "Set" 0 "Off/Disabled" ;
VAL_ 2566844926 CruiseControlStates 7 "Not available" 6 "Accel.Override" 5 "Set" 4 "Resume" 3 "Decelerate" 2 "Accelerate" 1 "Hold" 0 "Off/Disabled" ;
VAL_ 2566844926 CruiseControlActive 1 "switched on" 0 "switched off" ;
VAL_ 2566844926 BrakeSwitch 1 "pedal depressed" 0 "pedal released" ;
VAL_ 2566844926 ClutchSwitch 1 "pedal depressed" 0 "pedal released" ;
VAL_ 2566844926 ParkingBreakSwitch 1 "Parking brake set" 0 "Parking brake not set" ;
VAL_ 2566767358 FuelType 255 "Not available" 254 "Error" 28 "Dual Fuel - Diesel and LNG" 27 "Dual Fuel - Diesel and CNG" 26 "Comp. or Liquefied Natrual Gas" 25 "Bi-fuel using diesel" 24 "Bi-fuel using NG" 23 "Natural Gas (NG)" 22 "Hybrid in regeneration mode" 21 "Hybrid battery, combustion eng." 20 "Hybrid using battery" 19 "Hybrid using diesel engine" 18 "Hybrid using gasoline on ethanol" 17 "Hybrid using gasoline" 16 "Bi-fuel battery, combustion eng." 15 "Bi-fuel using battery" 14 "Bi-fuel using propane" 13 "Bi-fuel using CNG" 12 "Bi-fuel using LPG" 11 "Bi-fuel using ethanol" 10 "Bi-fuel using methanol" 9 "Bi-fuel using gasoline" 8 "Battery/electric" 7 "Propane" 6 "Compressed Natrual Gas (CNG)" 5 "Liquified Petroleum Gas (LPG)" 4 "Diesel" 3 "Ethanol" 2 "Methanol" 1 "Gasoline/petrol" 0 "Not available" ;
VAL_ 2566749694 TelltaleStatus9 7 "not available" 3 "Condition Info" 2 "Condition yellow" 1 "Condition red" 0 "off" ;
VAL_ 2566749694 TelltaleStatus8 7 "not available" 3 "Condition Info" 2 "Condition yellow" 1 "Condition red" 0 "off" ;
VAL_ 2566749694 TelltaleStatus7 7 "not available" 3 "Condition Info" 2 "Condition yellow" 1 "Condition red" 0 "off" ;
VAL_ 2566749694 TelltaleStatus6 7 "not available" 3 "Condition Info" 2 "Condition yellow" 1 "Condition red" 0 "off" ;
VAL_ 2566749694 TelltaleStatus5 7 "not available" 3 "Condition Info" 2 "Condition yellow" 1 "Condition red" 0 "off" ;
VAL_ 2566749694 TelltaleStatus4 7 "not available" 3 "Condition Info" 2 "Condition yellow" 1 "Condition red" 0 "off" ;
VAL_ 2566749694 TelltaleStatus3 7 "not available" 3 "Condition Info" 2 "Condition yellow" 1 "Condition red" 0 "off" ;
VAL_ 2566749694 TelltaleStatus2 7 "not available" 3 "Condition Info" 2 "Condition yellow" 1 "Condition red" 0 "off" ;
VAL_ 2566749694 TelltaleStatus15 7 "not available" 3 "Condition Info" 2 "Condition yellow" 1 "Condition red" 0 "off" ;
VAL_ 2566749694 TelltaleStatus14 7 "not available" 3 "Condition Info" 2 "Condition yellow" 1 "Condition red" 0 "off" ;
VAL_ 2566749694 TelltaleStatus13 7 "not available" 3 "Condition Info" 2 "Condition yellow" 1 "Condition red" 0 "off" ;
VAL_ 2566749694 TelltaleStatus12 7 "not available" 3 "Condition Info" 2 "Condition yellow" 1 "Condition red" 0 "off" ;
VAL_ 2566749694 TelltaleStatus11 7 "not available" 3 "Condition Info" 2 "Condition yellow" 1 "Condition red" 0 "off" ;
VAL_ 2566749694 TelltaleStatus10 7 "not available" 3 "Condition Info" 2 "Condition yellow" 1 "Condition red" 0 "off" ;
VAL_ 2566749694 TelltaleStatus1 7 "not available" 3 "Condition Info" 2 "Condition yellow" 1 "Condition red" 0 "off" ;
VAL_ 2365484286 VehicleOverspeed 1 "Overspeed" 0 "No overspeed" ;
VAL_ 2365484286 VehicleMotion 1 "Vehicle motion detected" 0 "Vehicle motion not detected" ;
VAL_ 2365484286 TachographPerformance 1 "Performance analysis" 0 "Normal performance" ;
VAL_ 2365484286 SystemEvent 1 "tachogr. Event" 0 "no tachogr. Event" ;
VAL_ 2365484286 HandlingInformation 1 "handling information" 0 "no handling information" ;
VAL_ 2365484286 Driver2Card 1 "Card present" 0 "Card not present" ;
VAL_ 2365484286 Driver1Card 1 "Card present" 0 "Card not present" ;
VAL_ 2365484286 Driv2WorkingState 7 "not available" 6 "Error" 3 "Drive" 2 "Work" 1 "Driver available" 0 "Rest" ;
VAL_ 2365484286 Driv2TimeRelState 21 "not available" 20 "Error" 6 "16h reached" 5 "15min before 16h" 4 "9h reached" 3 "15min before 9h" 2 "4,5h reached" 1 "15min bef. 4,5h" 0 "normal" ;
VAL_ 2365484286 Driv1WorkingState 7 "not available" 6 "Error" 3 "Drive" 2 "Work" 1 "Driver available" 0 "Rest" ;
VAL_ 2365484286 Driv1TimeRelStates 21 "not available" 20 "Error" 6 "16h reached" 5 "15min before 16h" 4 "9h reached" 3 "15min before 9h" 2 "4,5h reached" 1 "15min bef. 4,5h" 0 "normal" ;
VAL_ 2365484286 DirectionIndicator 1 "Reverse" 0 "Forward" ;
VAL_ 2566771198 DiagnosticsSupported 3 "don't care" 1 "diagnostics is supported" 0 "diagnostics is not supported" ;
VAL_ 2566771198 RequestsSupported 3 "don't care" 1 "request is supported" 0 "request not supported" ;
VAL_ 2559835902 ErrorCode 255 "Not Available" 254 "Reserved" 6 "Reserved" 5 "Other" 4 "Pending NAME not set" 3 "Checksum does not match" 2 "Item conflict" 1 "Item(s) not allowed to change" 0 "Security not satisfied" ;
VAL_ 2559835902 CommandedIndustryGroup 6 "Reserved for SAE" 7 "Reserved for SAE" 5 "IndustrialProcessCtrlStationary" 4 "Marine" 3 "Construction" 2 "Agricultural and Forestry" 1 "On-Highway" 0 "Global" ;
VAL_ 2559835902 CommandedManufacturerCode 1863 "Thomas G. Faria Co." 1862 "Sanshin" 1861 "Vector North America (formerly Vector Cantech)" 1860 "MMP" 1859 "Kvasar AB" 1858 "Litton" 1857 "Simrad" 1856 "Trimble" 1855 "Furuno USA" 1854 "Northstar Technologies" 1853 "Japan Radio Co" 1852 "Navionics" 1851 "RayMarine" 1850 "Seastar Solutions (formerly Teleflex)" 1569 "621 Technologies Inc." 1164 "SEG Automotive" 1163 "DFX Technologies LLC" 1162 "PEL-tuote Oy" 1161 "Griessbach GmbH" 1160 "MG Energy Systems B.V." 1159 "Bel Power Solutions" 1158 "Technoton Electronics" 1157 "Carriergistics" 1156 "Nokian Tyres" 1155 "LACOS Computerservice GmbH" 1154 "TBS Electronics BV" 1153 "Kawasaki Heavy Industries, Ltd." 1152 "Vredo Dodewaard B.V." 1151 "Orca Technologies AS" 1150 "BSB Artificial Intelligence GmbH" 1149 "Wuxi Shengbang Electronics Co., Ltd" 1148 "Stercom Power Solutions GmbH" 1147 "Dana Inc." 1146 "Rometron" 1145 "Kiwi Yachting" 1144 "Troo Corporation" 1143 "Elektro-Szoft 2000" 1142 "Truma" 1141 "MRS Electronic GmbH & Co. KG" 1140 "Across Oceans Systems Ltd." 1139 "ASP Technology" 1138 "Micro-Sensor GmbH" 1137 "SIKO GmbH" 1136 "Primosensor GmbH" 1135 "Japan Aviation Electronics Industry, Limited" 1134 "Master Schools at Ostbahnhof" 1133 "MEGATRON Elektronik GmbH & Co. KG" 1132 "Tokachi Zaidan" 1131 "Guliwer electronics s.r.o." 1130 "Vitesco Technologies" 1129 "Spectrolytic GmbH" 1128 "Citoon Electronic Technology (Tianjin) Co., Ltd." 1127 "ElectroMaax" 1126 "Auralix" 1125 "Griffith-Elder & Co. Ltd." 1124 "Fortron Agriculture" 1123 "QP Hydraulics" 907 "strautmann" 906 "MOBA AG" 905 "ASA Electronics" 904 "Equipment Safety Systems Pty. Ltd. (EQSS)" 903 "InMotion" 902 "Bucher Hydraulics" 901 "Zivan Srl" 900 "OSB AG" 899 "Lippert Components, Inc" 898 "Josef Kotte Landtechnik GmbH & Co. KG" 897 "Dot Technology Corp." 896 "NextFour Solutions Ltd" 895 "Peloton Technology" 894 "Rhodan Marine Systems of Florida LLC" 893 "KlinkTechnics Ltd." 892 "Mectronx Corp" 891 "CarrierWeb" 890 "L3 Technologies, Inc." 889 "SANY America Inc" 888 "Carma Systems Inc" 887 "Hyperdrive Innovation Limited" 886 "Hitachi Zosen Corporation" 885 "SICK Stegmann GmbH" 884 "Sure Grip Controls Inc." 883 "Swift Navigation, Inc." 882 "BHTronik GmbH & Co. KG" 881 "Sovema" 880 "Revision Military" 879 "PG Trionic, Inc." 878 "FOTON" 877 "SICK ATech GmbH" 876 "SUCO Robert Scheuffele GmbH & Co. KG" 875 "Salvarani S.r.l." 874 "MTA S.p.A." 873 "Garnet Instruments Ltd." 872 "Kählig Antriebstechnik GmbH" 871 "Superior Tech Inc" 870 "Textron Fleet Management" 869 "Intercomp" 868 "Data Panel Corp" 867 "Skeleton Technologies" 866 "Netradyne, Inc." 865 "MyEasyFarm" 864 "Streamline Transportation Technologies Inc." 863 "SMAG" 862 "Prospec Electronics" 861 "Adel System S.r.l." 860 "Michelin" 859 "Valor" 858 "Littelfuse" 857 "Zoomlion Heavy Industry NA, Inc" 856 "FarmFacts GmbH" 855 "Toshiba Infrastructure Systems & Solutions Corporation" 1122 "GT Inc." 1121 "Platform Science" 1120 "Elettromedia s.r.l." 1119 "Balmar LLC" 1118 "L3Harris ASV" 1117 "LG Chem, Ltd" 1116 "HR Agrartechnik GmbH" 1115 "Gems Sensors & Controls" 1114 "Bob's Machine" 1113 "iVolve Pty Ltd" 1112 "Bollinger Motors" 1111 "SEPPI M." 1110 "Analytic Systems Ware (1993) Ltd." 1109 "Dockmate" 1108 "ORBCOMM" 1107 "Dräger Safety" 1106 "Great Dane LLC" 1105 "Redekop Manufacturing" 1104 "The Toro Company" 1103 "Diesel Laptops" 1102 "Carl Geringhoff GmbH & Co. KG" 1101 "DIS Sensors B.V." 1100 "Smart Yachts International Limited" 1099 "MadgeTech, Inc" 1098 "Preh GmbH" 1097 "M2M Craft Co., Ltd" 1096 "Texense Sensors" 1095 "WEG Drives and Controls - Automação Ltda" 1094 "Tokushu Denki" 1093 "innolectric" 1092 "Scheiber" 1091 "Wheel Monitor Inc." 1090 "E-T-A Circuit Breakers Ltd" 1089 "Carrosserie HESS AG" 1088 "E-T-A Circuit Breakers" 1087 "ITPhotonics S.r.l." 1086 "Life Racing Ltd" 1085 "Wet Sounds, LLC" 1084 "Shadow-Caster LED lighting LLC" 1083 "Nauticoncept" 1082 "TÜMOSAN Engine and Tractor Co." 1081 "Imcon Electronics, s.r.o." 1080 "Epsilor-Electric Fuel Ltd." 1079 "Carl Zeiss Spectroscopy GmbH" 1078 "GE Appliances" 1077 "Ymer Technology" 1076 "DOGA S.A." 1075 "Uniden America Corporation" 1074 "Kindhelm / Navigs Oy" 1073 "Manitou Equipment America LLC" 1072 "La Marche Manufacturing Company" 1071 "MACH SYSTEMS s.r.o." 1070 "Quick-teck Electronics Ltd" 1069 "Lithionics Battery LLC" 1068 "Zapi S.p.A." 1067 "Tecomec S.r.l." 1066 "Spot Zero Water" 1065 "CALYPSO Instruments" 1064 "Omnitech Robotics Inc." 1063 "SolSteer" 1062 "Marol Co Ltd" 1061 "Volvo Construction Equipment" 1060 "Scale-Tec" 1059 "Boatrax" 1058 "Bondioli & Pavesi SpA" 1057 "EquipmentShare" 1056 "Lithium Pros" 1055 "EXA Computing GmbH" 1054 "Schmotzer Hacktechnik GmbH & Co. KG" 1053 "Vetus Maxwell, Inc." 1052 "Pfreundt" 1051 "ProNav AS" 1050 "Spacenus GmbH" 1049 "S&S Cycle" 1048 "Agrivation UG" 1047 "Sonic Corporation" 1046 "Praxidyn" 1045 "CMR Group" 1044 "Xee" 1043 "Hyva" 1042 "engcon group" 1041 "EZ Lynk" 1040 "BPE Electronics Srl" 1039 "Liugong Dressta Machinery" 1038 "EMIT Technologies, Inc." 1037 "Dragonfly Energy Corp." 1036 "Bender GmbH & Co. KG" 1035 "Agres" 1034 "Siren Marine" 1033 "ECCO Safety Group" 1032 "SIMOL S.p.A." 1031 "Flintec UK Ltd." 1030 "Tume-Agri Oy" 1029 "The Marine Guardian LLC" 1028 "Autel Intelligent Technology Corp., Ltd" 1027 "Goldacres PTY LTD" 1026 "ZTR Control Systems, LLC" 1025 "eze System, Inc." 1024 "Inventus Power" 1023 "PEAK-System Technik GmbH" 1022 "ITC Inc" 1021 "Entratech Systems LLC" 1020 "Onyx Marine Automation s.r.l." 1019 "Codek Foundries" 1018 "Flex TTS" 1017 "Caldaro AB" 1016 "Röhren- und Pumpenwerk BAUER GmbH" 1015 "SECURITAG SAS" 1014 "Briri Maschinenbau GmbH" 1013 "Allochis E-Tec" 1012 "Rhodan Marine Systems of Florida LLC" 1011 "Soundmax Electronics Ltd" 1010 "Agricultural Industry Electronics Foundation e.V." 1009 "TouchTronics, Inc." 1008 "Lintest Systems LLC" 1007 "Maschinenfabrik Meyer-Lohne GmbH" 1006 "Proterra" 1005 "TSE Brakes, Inc." 1004 "Ultraflex SpA" 1003 "technotrans SE" 1002 "Kussmaul Electronics Co." 1001 "Cleral Inc." 1000 "Landmaschinen Wienhoff GmbH" 999 "TerraTroniq B.V." 998 "Transcell Technology Inc" 997 "Xenta Systems Srl" 996 "Eniquest Pty Ltd" 995 "Circuitlink Pty Ltd." 994 "Morris Industries Ltd." 993 "Alelion Energy Systems AB" 992 "MarineIOT LLC" 991 "Deutronic Elektronik GmbH" 990 "SAMSUNG SDI Co., Ltd." 989 "Flux-Geräte GmbH" 988 "Voith Turbo" 987 "Baltic Car Equipment" 986 "AAMP Global" 985 "NLR, LLC" 984 "E-T-A Elektrotechnische Apparate GmbH" 983 "Dezwaef NV" 982 "Briggs & Stratton Corporation" 981 "Kobelt Manufacturing Co. Ltd" 980 "Gussi Italia S.R.L." 979 "McHale" 978 "Canfield Connector" 977 "Emerson Electric Co." 976 "Derive Systems, Inc." 975 "Siemens AG" 974 "Pico Technology Limited" 973 "Zasso GmbH" 972 "Axion AG" 971 "B+B Smartworx" 970 "Jaboni Power Products, LLC" 969 "Blue Sea Systems" 968 "Cox Powertrain Limited" 967 "Moteck Electric Corp." 966 "VisibleFarm" 965 "Ro-Sys Software" 964 "AgroVIR Kft" 963 "Thomason Jones Company, LLC" 962 "Timbolier Industries, Inc." 961 "POK SAS" 960 "Vemcon GmbH" 959 "Cascade Corporation" 958 "NHK MEC Corporation" 957 "Sierra Wireless Inc" 956 "Piher Sensors & Controls S.A." 955 "Hottinger Baldwin (Suzhou) Electronic Measurement Technology Co., Ltd." 954 "Setec Pty Ltd" 953 "Curtiss-Wright" 952 "Tan Delta Systems Ltd" 951 "Exor International S.p.A." 950 "RE:Lab s.r.l." 949 "Škoda Electric a.s." 948 "Donix" 947 "Gerd Bär GmbH" 946 "Hydac Tecnologia Ltda" 945 "Equalizer AG" 944 "ZONTISA Marine SL" 943 "FISCHER AG Präzisionspindeln" 942 "Vogelsang GmbH & Co. KG" 941 "Navya" 940 "Dometal Oy" 939 "Warn Industries, Inc." 938 "LEVEL Systems" 937 "Precision Circuits Inc" 936 "Hi-tech Millennium" 935 "Meels GmbH & Co. KG" 934 "Farmobile, Inc." 933 "Delta Mobile Systems, Inc." 932 "Discover Battery" 931 "Enertec Marine Ltd" 930 "Ecotronix Corp." 929 "Jl Marine Systems, Inc." 928 "EAO Automotive GmbH & Co. KG" 927 "Saicon" 926 "Buhler Industries Inc." 925 "GW Lisk Company" 924 "PAS Peschak Autonome Systeme GmbH" 923 "ELTEK S.p.A." 922 "Terberg Benschop B.V." 921 "ROPA Fahrzeug- und Maschinenbau GmbH" 920 "MTD Consumer Group Inc." 919 "Furrion LLC" 918 "AMW Machine Control, Inc" 917 "Sentinel d.o.o." 916 "Turck Inc." 915 "Dosificacion y sistemas electronicos S.L. (DSE)" 914 "ZETOR TRACTORS a.s." 913 "Toyota Motor Corporation" 912 "Steyr Motors GmbH" 911 "Nautic-On" 910 "Hermann Paus Maschinenfabrik GmbH" 909 "Marines Co., Ltd." 908 "Chonbuk National University Department of Electronics" 854 "GEMAC Chemnitz GmbH" 853 "Teledyne RESON B.V." 852 "Velvac Inc" 851 "Novotechnik Messwertaufnehmer OHG" 850 "Geoprospectors GmbH" 849 "MTS Maschinentechnik Schrode AG" 848 "ningupex" 847 "Oceanvolt" 846 "L3 Magnet-Motor" 845 "GMB Güstrower Maschinenbau GmbH" 844 "FELL AS" 843 "Hendrickson Truck Commercial Vehicle Systems" 842 "DigiDevice Srl" 841 "Agra-GPS" 840 "E.S.T.E. Srl" 839 "Indexator Rotator Systems AB" 838 "Teamsurv Ltd" 837 "Famic Technologies Inc." 836 "Signature4" 835 "PetTrack Ltd." 834 "Pioneer Microsystems, Inc." 833 "Electrum Automation AB" 832 "Heizomat Gerätebau-Energiesysteme GmbH" 831 "DOK-ING Ltd." 830 "Ultra Motion LLC" 829 "Drov Technologies, Inc." 828 "AgriBrink Inc." 827 "INmatix Technology Group Ltd" 826 "Lewmar Marine Inc" 825 "BPW Hungária" 824 "Undheim Systems AS" 823 "ACEINNA, Inc (formerly MEMSIC, Inc)" 822 "Bren-Tronics, Inc." 821 "Thorsen Teknik A/S" 820 "DIaLOGIKa Gesellschaft fuer angewandte Informatik mbH" 819 "Preco Electronics" 818 "HGNSS" 817 "TE Connectivity Sensor Solutions" 816 "UniStrong" 815 "FLIR Systems, Inc." 814 "Kronotech Srl (formerly Soltec Soluzioni Tecnologiche Srl)" 813 "Thales Suisse SA" 812 "Torch Technologies" 811 "Blue Water Desalination" 810 "Dutch Power Company" 809 "HMS Industrial Networks AB" 808 "RIMEX Supply Ltd." 807 "Schneider-Electric" 806 "Charge Automotive Ltd" 805 "Gundersen & Løken AS" 804 "ASA Electronics" 803 "Gill Sensors & Controls Limited" 802 "SPBI (Bj Technologie)" 801 "LOR Manufacturing Company Inc." 800 "Delta-Q Technologies" 799 "Stillwater Designs and Audio, Inc. - KICKER" 798 "Lumishore Ltd" 797 "Tides Marine" 796 "Canadian Automotive Industries Ltd" 795 "Broyda Enterprises Pty Ltd" 794 "Shihlin Electric & Engineering Corporation" 793 "James Fisher Prolec" 792 "Kostal Mexicana" 791 "AUTEC" 790 "VACALL" 789 "GRADALL" 788 "MoTeC Pty Ltd" 787 "Abertax Technologies Limited" 786 "Johnson Matthey Battery Systems" 785 "Fischer Panda GmbH" 784 "CM Automotive Systems, Inc." 783 "Loup Electronics Inc." 782 "AVR bv (formerly AVR bvba)" 781 "Poly-Planar LLC" 780 "AVID Technology Ltd" 779 "RLC Electronic Systems" 778 "Seakeeper Inc." 777 "Ocean Signal Ltd" 776 "HMI Systems LLC" 775 "ZIEHL-ABEGG Automotive GmbH" 774 "Taisho Corporation" 773 "Clarion Corporation of America" 772 "Blink Marine" 771 "Shaw Development, LLC" 770 "MONOSEM" 769 "Trombetta" 768 "Flores Automation, LLC" 767 "Alliance Wireless Technologies Inc." 766 "Epec Oy" 765 "GIGAVAC" 764 "Bednar FMT s.r.o." 763 "AT-Systems BVBA" 762 "ROJ s.r.l." 761 "MITA OLEODINAMICA S.p.A." 760 "Bernecker + Rainer Industrie Elektronik GmbH" 759 "Hydro-Gear" 758 "Banner Engineering Corp." 757 "IMPCO Technologies" 756 "Maschio Gaspardo S.P.A." 755 "Firefly Integrations" 754 "Parker Hannifin Corp., Automation Group" 753 "AIROD Technologies" 752 "Deep Sea Electronics Plc" 751 "Pacific Track" 750 "Joskin SA" 749 "Chart Inc." 748 "IFRA SRL - ISOTTA" 747 "Agratronix" 746 "SureFire Ag Systems, Inc." 745 "Cidra Corporate Services Inc." 744 "Woosung Engineering Co., Ltd." 743 "Daemyung Elevator Co., Ltd." 742 "EROAD" 741 "Carling Technologies" 740 "e-Traction" 739 "LXNAV d.o.o." 738 "Blue Ink Technologies" 737 "Balluff GmbH" 736 "Terex Aerial Work Platforms - Genie" 735 "AEM Performance Electronics" 734 "REAPsystems" 733 "Geotab Inc. (formerly Intendia S.L.)" 732 "Gefran S.p.A." 731 "Modine Manufacturing Company" 730 "BERTHOUD AGRICOLE" 729 "Liebherr" 728 "Streumaster (formerly Streumaster / Panien)" 727 "Dhoot Transmission Pvt Ltd." 726 "MIDORI PRECISIONS" 725 "Hitachi Construction Machinery Co., Ltd." 724 "Electronic Applications, Inc." 723 "Jabil Inc." 722 "Contelec AG" 721 "Hypro" 720 "WITZ Corporation" 719 "Cojali S. L." 718 "Micronet Inc" 717 "Yacht Devices Ltd" 716 "Eaton Control & Power Conversion Division (CPCD)" 715 "Autonnic Research Ltd" 714 "Kobashi Kogyo Co., Ltd." 713 "US Hybrid Corporation" 712 "LOR Manufacturing Company Inc." 711 "DAS Co., LTD" 710 "Greentronics Ltd." 709 "Marquardt GmbH" 708 "Lars Thrane A/S" 707 "Rochester Gauges Inc" 706 "Shanghai Diesel Engine Corporation Limited" 705 "SVAB Hydraulik AB" 704 "JL Audio, Inc." 703 "Hydro Tab Marine Engineering" 702 "Weichai Power Co., Ltd." 701 "BigRoad Inc." 653 "AEV, spol. s r. o." 652 "MicroControl GmbH & Co. KG" 651 "Takakita Co, Ltd." 650 "Seiko Epson Corp." 649 "Control-Q B.V." 648 "OJSC Ekran" 647 "Siloking" 646 "Veenhuis Machines B.V." 645 "esd electronic system design gmbh" 644 "KUS USA" 643 "Bogballe A/S" 642 "Moog / Aspen Motion Technologies" 641 "Diverse Yacht Services" 640 "Power Solutions International" 639 "Startec s.r.l." 638 "KVH Industries, Inc." 637 "Bavaria Yachtbau GmbH" 636 "Divelbiss Corporation" 635 "Argo Tractors S.p.A." 634 "Rocky Research" 633 "TORC Robotics" 632 "Pepperl+Fuchs GmbH" 631 "Reltima" 630 "SmartDrive Systems Inc." 629 "Agri Info Design, Ltd." 628 "Falck Schmidt Defence Systems" 627 "Radio Ocean" 626 "AVL DiTEST GmbH" 625 "Global MRV Inc." 624 "Blackbox Machine Control Pty Ltd" 623 "Xirgo Technologies" 622 "Floyd Bell Inc" 621 "Hagie Manufacturing Company" 620 "Sevcon Ltd." 619 "Right Weigh Load Scales" 618 "Evrard SA" 617 "Zero Emission Vehicles" 616 "SMART-TEC s.r.o." 615 "Networkfleet, Verizon Telematics" 614 "ARLT Technologies GmbH" 613 "HKS Co., Ltd." 612 "Samwon IT" 611 "Esterline" 610 "Trail Tech" 609 "Walvoil S.p.A." 608 "Gale Banks Engineering" 607 "Knappco/Civacon" 606 "Intellian Technologies" 605 "Aventics GmbH" 604 "Rototilt Group AB (formerly Indexator Rototilt Systems AB)" 603 "Kereval" 602 "Nomad Digital Ltd." 601 "Navitas Systems" 600 "Aquatic AV" 142 "TRW Automotive (Commercial Steering Systems)" 141 "Thales Navigation Ltd." 140 "Lowrance Electronics, Inc." 139 "Caterpillar Trimble Control Technologies (CTCT), LLC" 138 "Georg Fritzmeier GmbH & Co. KG" 137 "Maretron" 136 "Komatsu Ltd" 135 "Airmar Technology Corporation" 134 "Iris Technology Ltd" 133 "Bucher Schoerling GmbH" 132 "Mulag-Fahrzeugwerk" 131 "ITT Industries" 130 "Nido - Universal Machines B.V." 129 "OMNEX Control Systems Inc." 128 "Gerhard Duecker GmbH & Co. KG" 127 "Holland USA" 126 "Driver Tech" 125 "Nevada Automotive Test Center" 447 "Great Plains Mfg." 446 "CertTech, L.L.C." 445 "KAT MECHATRONIC, Electronic Product Division" 444 "ITT Power Solutions" 443 "SignalQuest, Inc." 442 "Horsch Maschinen GmbH" 441 "PTG Reifendruckregelsysteme GmbH" 440 "Cummins Power Generation" 439 "Hyundai Heavy Industries" 438 "Comar Systems Ltd" 437 "Digital Yacht Limited" 436 "Kinze Manufacturing" 435 "Zunhammer GmbH" 434 "Stored Energy Systems" 433 "Rowe Electronics" 432 "S&A Systems, Inc." 431 "Tohatsu Corporation" 430 "Auteq Telematica S.A." 429 "Rota Engineering Ltd." 425 "Methode Electronics Inc, MDI" 424 "Odyne LLC" 423 "BSM Wireless, Inc." 422 "True Heading AB" 421 "Vertex Standard Co, Ltd" 420 "Vermeer Corporation, ACS Group" 419 "Fusion Electronics Ltd" 418 "Intellistick Inc" 417 "KZValve" 416 "Kubota Corporation" 415 "Valid Manufacturing Ltd." 414 "Cattron Group International" 413 "Datapross Nijbroek bv" 412 "WebTech Wireless Inc." 411 "Hy-Drive Technologies Ltd." 410 "COBO S.p.A. Divisione 3B6" 409 "Transfluid S.r.L." 408 "Corvus Energy Ltd." 407 "Comtech Mobile Datacom" 406 "Vecima Networks Inc." 405 "Wema System AS" 404 "Com Nav Marine Ltd" 403 "Trackwell ADS, Inc." 402 "Simma Software, Inc." 401 "Torqeedo GmbH" 400 "Livorsi Marine" 399 "ISEKI & Co., Ltd." 398 "Hilite International" 397 "Sanyo-kiki Co Ltd." 396 "Beyond Measure" 395 "GENTEC S.R.L." 394 "Capi 2 Nederland B.V." 393 "Harvest Tec, Inc" 124 "Hydac Electronic" 123 "Basler Electric" 122 "FG Wilson (Engineering) Limited" 121 "HED (Hydro Electronic Devices, Inc.)" 120 "RDS Technology Ltd" 119 "IntegriNautics  " 118 "Intron GmbH" 117 "HUSCO International" 116 "BEELINE Technologies" 115 "NACCO Materials Handling Group, Inc." 114 "EControls, Inc." 113 "Stress-Tek, Inc." 112 "MECALAC" 111 "Bernard Krone Holding SE & Co. KG (formerly Maschinenfabrik Bernard Krone GmbH)" 110 "EPIQ Sensor-Nite" 109 "TeeJet Technologies Denmark (formerly LH Technologies ApS)" 108 "WTK-Elecktronik GmbH" 107 "Grimme Landmaschinen GmbH & Co. KG" 106 "BAE Systems Controls, Inc." 105 "Kiepe Elektrik GmbH & Co. KG" 104 "CLAAS KGaA mbH (formerly CLAAS Selbstfahrende Erntemaschinen GmbH)" 700 "K-Tec Earthmovers Inc." 699 "Harman International Industries" 698 "Scorpion Technologies Ltd." 697 "Ålö AB" 696 "DRS Network & Imaging Systems, LLC (DRS Technologies)" 695 "Weldon Technologies" 694 "GasTOPS Ltd." 693 "Agility Fuel Solutions (formerly Agility Fuel Systems)" 692 "Tanhay Corporation" 691 "Digitroll Agricultural Electronics" 690 "LINAK A/S" 689 "Aarcomm Systems Inc" 688 "Rockford Corp" 687 "Flight Systems, Inc." 686 "Taigene Electric Machinery Corp." 685 "ANEDO (formerly ANEDO Ltd.)" 684 "KEB" 683 "Fosen Elektro" 682 "Eckelmann AG" 681 "BEDIA Motorentechnik GmbH & Co. KG" 680 "AMVAC Chemical Corporation" 679 "OXE Marine AB (formerly Cimco Marine AB)" 678 "KeepTruckin, Inc." 677 "DSA Daten- und Systemtechnik GmbH" 676 "Danfoss IXA A/S" 675 "Kawasaki Motors Corp., USA" 674 "Yara International ASA" 673 "Caruelle Nicolas" 672 "OPTIMA Concept" 671 "Innovative Controls Inc." 670 "STEMCO LP" 669 "Quantum Fuel Systems Technologies Worldwide, Inc" 668 "MacDon Industries Ltd." 667 "Bartec" 666 "Schaeffler Technologies AG & Co., KG" 665 "Gebr. Bode GmbH & Co. KG" 664 "Level Developments Ltd" 663 "Delta Systems, Inc" 662 "Kissling Elektrotechnik GmbH" 661 "SPAL Automotive S.r.l." 660 "Auto-Gaz Centrum" 659 "Data Panel Corp." 658 "Shenzhen Jiuzhou Himunication Technology Co., Ltd" 657 "Terzo Power Systems" 656 "PRO SOLUS do Brasil" 655 "Genge & Thoma AG" 654 "Kohler Power Systems, Detroit Engine Development Center (DEDC)" 599 "Spudnik Equipment Co, LLC" 598 "ABB Turbo Systems Ltd" 597 "Hydac Filter Systems GmbH" 596 "Brunelco Electronic Innovators B.V." 595 "CustomWare" 594 "Kongsberg Automotive" 593 "Sensata Technologies" 592 "tecsis GmbH" 591 "United States Coast Guard" 590 "ARGO-HYTOS GMBH" 589 "MICO, Inc." 588 "Vignal Systems" 587 "JCA Electronics" 586 "Suzuki Motor Corp" 585 "Industrial Electronic Controls" 584 "CarMedialab GmbH" 583 "Yachtcontrol" 582 "Innovative Software Engineering" 581 "Väderstad - Verken AB" 580 "San Jose Technology, Inc." 579 "KVH Industries, Inc." 578 "advanSea" 577 "Denchi Power Ltd  (formerly ABSL Power Solutions Limited)" 576 "Vectia" 575 "Lytx" 574 "Vishay Precision Group" 573 "Orolia Ltd" 572 "Fasse Valves" 571 "Marinecraft Co., Ltd." 570 "frenzel + berg electronic GmbH & Co. KG" 569 "LORD MicroStrain Sensing Systems" 568 "Makersan Ltd. Co." 567 "Lithiumstart LLC" 566 "Geode Technology, Inc." 565 "Micro-Trak Systems, Inc." 564 "Auto Power Electronic" 563 "LOHR Sistemas Eletronicos LTDA" 562 "Bombardier Transportation GmbH" 561 "b-plus GmbH" 560 "Iowa State University, Agricultural and Biosystems Engineering" 559 "Four Peaks Navigation" 558 "Davis Instruments Corp." 557 "Rockson Automation GmbH" 556 "Doosan Infracore Norway" 555 "Sasaki Corporation" 554 "iris-GmbH infrared & intelligent sensors" 553 "KIB Electronics" 552 "Matsuyama Plow Mfg Co, Ltd" 551 "Wexler CSD Ltd." 550 "SUN-A Corporation" 549 "ROAD Deutschland GmbH" 548 "TM4 Inc." 547 "Thomson Linear LLC" 546 "Maruyama Mfg Co, Inc." 545 "GS Hydraulics" 544 "Au Group Electronics" 543 "BAUER Maschinen GmbH" 542 "Dinamica Generale s.p.a." 541 "Total Fire Systems, Inc." 540 "Dinex A/S" 539 "Mobileview" 538 "Crop Ventures, Inc." 537 "Schrader Electronics Ltd." 536 "SSI Technologies" 535 "MOTORPAL, a.s." 534 "Webasto Thermo & Comfort SE" 533 "Doran Manufacturing, LLC" 532 "Onwa Marine Electronics Co Ltd." 531 "Genge & Thoma AG" 530 "NMEA" 529 "National Instruments Korea" 528 "Hoganas AB, Electric Drive Systems" 527 "GKN Walterscheid GmbH" 526 "LOFA Industries, Inc" 525 "Rust Sales INC" 524 "Vomax Instrumentation Pty. Ltd." 523 "Reggio Emilia Innovazione" 522 "Nebraska Tractor Test Laboratory" 521 "Clever Devices Ltd." 520 "Trapeze" 519 "Peeters Landbouwmachines b.v." 518 "Transas USA Inc." 517 "Noland Engineering" 516 "AVAT Automation GmbH" 515 "GINAF Trucks Nederland B.V." 514 "DISTek Integration, Inc." 513 "Precision Technology (formerly FarmscanAg)" 512 "Inpower LLC" 511 "Burel Production (formerly Sulky)" 510 "Marinesoft Co. Ltd" 509 "MOTORTECH GmbH" 508 "Transtech Innovations" 507 "ISOBUS Test Center" 506 "IHI STAR Machinery Corporation" 505 "Yetter Farm Equipment" 504 "Vesper Marine" 503 "Naviop S.R.L." 502 "Attwood Corporation" 501 "Agrotronix S.A." 500 "Oxbo International Corporation" 499 "LCJ Capteurs" 498 "Innovative Design Solutions, Inc." 497 "SENTRON Sistemas Embarcados" 496 "W. Gessmann GmbH" 495 "HOLMER Maschinenbau GmbH" 494 "Synerject" 493 "Watcheye" 492 "Inergy Automotive Systems" 491 "Penny and Giles Ltd" 490 "QuikQ" 489 "Appareo Systems, LLC" 488 "The Charles Machine Works, Inc." 487 "DSE Test Solutions A/S" 486 "Westport Innovations Inc." 485 "MATT automotive" 484 "Headsight Inc." 483 "Valeo" 482 "Tricon Electronics" 481 "Chetco Digital Instruments" 480 "EnerDel, Inc." 479 "Vapor Bus International" 478 "OceanSat B.V." 477 "OilQuick AB" 476 "Hummingbird Marine Electronics" 475 "GME" 474 "Persen Technologies Inc." 473 "Boss Industries, Inc." 472 "Tenneco Inc." 471 "Sea Cross Marine AB" 470 "SI-TEX Marine Electronics" 469 "RA Consulting GmbH" 468 "Tyco Fire Protection Products" 467 "Lely Industries N.V." 466 "Veethree Electronics and Marine LLC" 465 "Ashcroft Inc" 464 "Leach International Corporation" 463 "PROBOTIQ" 462 "IHI Shibaura Machinery Corporation" 461 "HAWE Hydraulik SE" 460 "San Giorgio S.E.I.N." 459 "Alltek Marine Electronics Corp" 458 "Control Solutions, Inc." 457 "RUSELPROM-ElectricDrive Ltd" 456 "General Kinetics" 455 "ADZ NAGANO GmbH" 454 "NGK Spark Plug Co. Ltd" 453 "Cooper Bussmann" 452 "WIKA Alexander Wiegand SE & Co. KG" 451 "Parker Hannifin Corp" 450 "Dycor Technologies Ltd." 449 "Polaris Industries Inc" 448 "Stanadyne Corporation, Electronics Systems" 392 "Tianyuan Technology Co Ltd." 391 "Electronic Design for Industry, Inc" 390 "Partech Inc." 389 "Benchmark Electronics, Minnesota Division" 388 "Innomatix, LLC" 387 "Orscheln Products, LLC" 386 "JLG Automation BVBA" 385 "Johnson Outdoor Marine Electronics" 384 "Camano Light" 383 "MCL Industries" 382 "National Agriculture and Food Research Organization" 381 "B & G" 380 "Suntech International Ltd." 379 "Yamabiko Corporation" 378 "Glendinning Marine Products" 377 "ifm electronic gmbh" 376 "Quake Global" 375 "Williams Controls Inc." 374 "Northern Lights, Inc." 373 "Electronic Design Inc." 372 "Delphi" 371 "Heinzmann GmbH & Co. KG" 370 "Rolls-Royce Marine AS" 369 "Power Torque Engineering Ltd" 368 "HANSENHOF_electronic" 367 "Fliegl Agrartechnik" 366 "Viewnyx Corp." 365 "Digi-Star, LLC" 364 "OEM Controls Inc." 363 "BEI Duncan" 362 "Poettinger Landtechnik GmbH (formerly Alois Poettinger Maschinenfabrik GmbH)" 361 "InMach" 360 "HJS Emission Technology GmbH & Co KG   (formerly HJS Fahrzeugtechnik GmbH & Co KG)" 359 "Ludwig Bergmann GmbH" 358 "Victron Energy B.V." 357 "Hardi International A/S" 356 "Fischer Panda Generators, Inc" 355 "Mastervolt International B.V." 354 "Junkkari OY" 353 "Hegemon Electronics, Inc." 352 "SAME DEUTZ-FAHR GROUP S.p.A." 351 "Thrane & Thrane" 350 "Noris Marine Systems GmbH & Co KG" 349 "Suonentieto" 348 "Amazonen Werke H. Dreyer" 347 "Honeywell" 346 "Control Solutions" 345 "Korean Maritime University" 344 "Parvus Corporation" 343 "Baumer Group" 342 "THOMAS MAGNETE GmbH" 341 "Boning GmbH & Co" 340 "Continental AG" 339 "Competence Center ISOBUS e.V." 338 "GRAF-SYTECO" 337 "Carraro S.p.A." 336 "APE s.r.o." 335 "Evo Electric Ltd" 334 "Takata-Petri AG" 333 "Hadley Products Corporation" 332 "HWH Corporation" 331 "Horton, Inc." 330 "Kidde Aerospace and Defense" 329 "Deif A/S" 328 "Qwerty Electronik AB" 327 "Sonceboz SA" 326 "Akron Brass Company" 325 "ASM Automation Sensorik Messtechnik GmbH" 324 "Snap-on Diagnostics" 323 "Mobileye Vision Technologies Ltd." 322 "MICHENKA s.r.o." 321 "Ultra Electronics, Electrics" 320 "Miedema Landbouwwerktuigenfabriek B.V." 319 "Cadec Global" 318 "SAT Plan" 317 "Navtronics Bvba" 316 "ITT Flow Control" 315 "Icom Incorporated" 314 "CSM GmbH" 313 "Ilmor Engineering, Inc." 312 "Lectronix, Inc." 311 "Patrick Power Products" 310 "TECNORD srl" 309 "Krauss-Maffei Wegmann GmbH & Co. KG" 308 "Cyntrx" 307 "MAS Technologies" 306 "Sleipner Motor AB" 305 "NovAtel Inc" 304 "EmpirBus AB" 303 "CTS Corporation" 302 "Nissin Kogyo Co., LTD" 301 "Parker Hannifin (UK) Ltd FDE group" 300 "Systron Donner Automotive" 299 "Rauch" 298 "Holley Performance" 297 "Zonar Systems Inc" 296 "micro dynamics GmbH" 295 "BEP Marine" 294 "Grayhill Inc." 293 "Spyder Controls Corp." 292 "IKUSI - Angel Iglesias S.A." 291 "Groeneveld Transport Efficiency BV" 290 "Kuebler GmbH" 289 "Watlow" 288 "Mitsubishi FUSO Truck & Bus Corp." 287 "NTech Industries, Inc" 286 "Coelmo srl" 285 "Sea Recovery Corp" 284 "Mobile Tech Chile" 283 "CWF Hamilton & Co Ltd" 282 "Medallion Instrumentation Systems" 281 "Precision Governors LLC" 280 "Leica Geosystems Pty Ltd" 279 "Geometris LP" 278 "Takata Electronics" 277 "LHP Telematics" 276 "Aqua-Hot Heating Systems" 275 "Navico Egersund AS" 274 "LTW Technology Co., LTD" 273 "Active Research Limited" 272 "Gross Mechanical Laboratories, Inc" 271 "Cole Hersee" 270 "Tennant" 269 "Saft America Inc.,  Space & Defense Division" 268 "Accurate Technologies" 267 "Red Lion Controls, Inc" 266 "International Thermal Research Ltd" 265 "MTS Sensor Technologie GmbH" 264 "Autolync" 263 "IMMI" 262 "HydraForce, Inc" 261 "Red Dot Corporation" 260 "Reichhardt GmbH Steuerungstechnik" 259 "Jetter AG" 258 "ARAG" 257 "Honda Motor Co., Ltd" 256 "Tyco Electronics AMP" 255 "MEAS France" 254 "GE Sensing" 253 "Mobile Control Systems" 252 "Sensor-Technik Wiedemann GmbH" 251 "German Agricultural Society, Test Center (DLG)" 250 "Kuhn Group" 249 "Schaltbau GmbH" 248 "Cooper Standard Automotive Active Systems Group" 247 "ePULSE" 246 "Class 1, Inc" 245 "Capstan Ag Systems, Inc." 244 "Techno-Matic" 243 "eRide, Inc." 242 "Kokusandenki Co. Ltd" 241 "Schneider Automation SAS" 240 "Vanair Mfg" 239 "May & Scofield Ltd" 238 "ZF Friedrichshafen AG" 237 "Agtron Enterprises Inc" 236 "NORAC Systems International Inc" 235 "SailorMade Marine Telemetry - Tetra Technology Ltd." 234 "Mondial electronic GmbH" 233 "Yacht Monitoring Solutions Inc." 232 "TSD Integrated Controls" 231 "Topcon Positioning Systems, Inc." 230 "Saucon Technologies" 229 "Garmin International Inc." 228 "Unused (formerly ZF Marine Electronics)" 227 "Lykketronic A/S" 226 "Monaco Coach Corporation" 225 "SKF" 224 "EMMI Network, S.L." 223 "Vaueo Retarder Co., Ltd." 222 "Generac Power Systems, Inc." 221 "SiE" 220 "Beede Electrical Instrument Company, Inc" 219 "Cat OEM Solutions" 218 "Gits Manufacturing Company" 217 "RM Michaelides Software & Elektronik GmbH" 216 "Paneltronics Inc." 215 "Aetna Engineering/Fireboy-Xintex" 214 "MC elettronica Srl" 213 "CNH Belgium N.V." 212 "Sure Power Industries, Inc" 211 "DNA Group" 210 "Iteris, Inc." 209 "Bell Equip. Co. SA (PTY) LTD" 208 "Drew Technologies, Inc" 207 "Otto Engineering" 206 "port GmbH" 205 "SmarTire Systems Inc" 204 "The Morey Corporation" 203 "MILtronik GmbH" 202 "Curtis Instruments, Inc" 201 "Disenos y Tecnologia S.A." 200 "MGM Brakes" 199 "ACTIA Group (formerly Actia Corp)" 198 "Mystic Valley Communications" 197 "Mechron Power Systems" 196 "LEMKEN GmbH & Co KG" 195 "General Engine Products" 194 "TriMark Corporation" 193 "Jeppesen Marine" 192 "Floscan" 191 "XRS Corporation (formerly XATA Corporation)" 190 "Hella KGaA Hueck & Co" 189 "QUALCOMM" 103 "CLAAS E-Systems GmbH (formerly CLAAS E-Systems KGaA mbH & Co. KG)" 102 "AGCO (formerly AGCO GmbH & Co.)" 101 "Sensoria" 100 "VDO Technik AG" 99 "International Transmissions Ltd (ITL)" 98 "Mueller-Elektronik GmbH & Co" 97 "Ag Leader Technology, Inc." 96 "Mech@tronic IT GmbH" 95 "Pacific Insight Electronics Corp." 94 "CNH Industrial N.V. (formerly CNH Global N.V.)" 93 "Perkins Engines Company Ltd." 92 "Ag-Chem Equipment Co., Inc." 91 "BSG Bodensee Steuergeraete GmbH" 90 "Knorr-Bremse SfN GmbH" 89 "Kverneland Group, Electronics Division" 88 "Hemisphere GPS Inc (formerly Satloc Precision GPS)" 188 "EMP Corp" 187 "Air-Weigh" 186 "Altronic, Inc" 185 "Beede Electrical Instrument Company" 184 "EIA Electronics" 183 "KDS Controls, Inc" 182 "Vehicle Systems Engineering B.V." 181 "Coretronics, Inc." 180 "Smart Power Systems" 179 "TeeJet Technologies Springfield (formerly Midwest Technologies Illinois, LLC)" 178 "Continental Automotive GmbH (formerly Siemens VDO Automotive AG)" 177 "Diagnostic Systems Associates" 176 "Moritz Aerospace" 175 "Veris Technologies, Inc." 174 "AB Volvo Penta" 173 "Ryeso, Inc." 172 "Yanmar Co., Ltd. (formerly Yanmar Marine USA)" 171 "Topcon Electronics GmbH & Co. KG (formerly Wachendorff Elektronik GmbH & Co. KG)" 170 "Computronics Corporation Ltd." 169 "Marlin Technologies Inc." 168 "Xantrex" 167 "JLG Industries Inc" 166 "John Deere Electronic Solutions (formerly Phoenix International)" 165 "CPAC Systems AB" 164 "MTU Friedrichshafen GmbH (formerly DaimlerChrysler Off-Highway)" 163 "BRP Inc." 162 "Axiomatic Technologies" 161 "Offshore Systems (UK) Ltd" 160 "Nido" 159 "NTech Industries Inc" 158 "Firestone Industrial Products Company" 157 "ISSPRO Inc." 156 "ITT Industries - Cannon" 155 "Vetronix Corporation" 154 "Westerbeke Corporation" 153 "Woodward, Industrial Controls Division" 152 "elobau GmbH & Co. KG" 151 "Raven Industries, Inc." 150 "Fleetguard" 149 "Holset" 148 "Blue Water Data, Inc." 147 "Nautibus electronic GmbH" 146 "Maxima Technologies" 145 "MurCal Controls" 144 "Mercury Marine" 143 "W. Gmeiner GmbH & Co." 87 "J.C. Bamford Excavators Ltd (JCB)" 86 "C. E. Niehoff & Company" 85 "Kohler Co" 84 "New Holland UK Limited" 83 "Bendix VORAD Technologies (formerly Eaton VORAD Technologies)" 82 "Bobcat/Ingersoll-Rand (formerly Melroe/Ingersoll-Rand)" 81 "Fire Research Corp." 80 "Twin Disc, Inc." 79 "Daimler Benz AG - Engine Division (PBM)" 78 "Frank W. Murphy Manufacturing, Inc" 77 "Deere Power Systems Group" 76 "unused (formerly Deere & Co, Construction Division)" 75 "Deere & Co, Agricultural Division" 74 "Eaton Axle-Brake Division" 73 "LeTourneau, Inc." 72 "Sisu Corporation" 71 "Vansco Electronics Ltd." 70 "Flex-coil Limited" 69 "Trimble Navigation" 68 "Scania" 67 "John Deere Coffeyville Works (formerly Funk Manufacturing Company)" 66 "John Deere Construction Equipment Division" 65 "MAN Nutzfahrzeuge AG" 64 "Unused (formerly SpectraPrecision Laserplane, then SpectraPhysics)" 63 "ZF Industries Inc." 62 "Wabco" 61 "Volvo Truck Corp." 60 "Volvo Trucks North America Inc." 59 "VES Inc." 58 "SPX Corporation, OTC Div" 57 "Danfoss  (formerly Sauer Sundstrand Co, then Sauer-Danfoss Co)" 56 "SAIC" 55 "Ryder System Inc." 54 "Meritor Wabco" 53 "Continental Automotive Systems US, Inc. (formerly Rockwell Land Transportation)" 52 "Meritor Automotive, Inc. (formerly Rockwell Automotive)" 51 "Robert Bosch GmbH" 50 "Robert Bosch Corp" 49 "RE America Inc." 48 "Pollak Alphabet" 47 "Phillips Semiconductor" 46 "Noregon Systems, Inc  (formerly Parasoft Computing Solutions)" 45 "PACCAR" 44 "Nippondenso Co. Ltd." 43 "International Truck and Engine Corporation - Vehicle Electronics (formerly Navistar Intl Trans Corp.)" 42 "International Truck and Engine Corporation - Engine Electronics  (formerly Navistar Intl Trans Co., Engine Electronics)" 41 "Motorola Inc." 40 "Motorola AIEG Inc." 39 "Microfirm Inc." 38 "Micro Processor Systems Inc." 37 "Mack Trucks Inc." 36 "Lucas Ind." 35 "Kenworth Truck Co." 34 "Kelsey Hayes Co." 33 "John Deere" 32 "Jacobs Vehicle Systems" 31 "J Pollak Corp" 30 "Isuzu Motors Ltd" 29 "Hino Motors Ltd." 28 "Grote Ind. Inc." 27 "GMC" 26 "General Motors Corp, Service Technology Grp" 25 "Daimler Trucks North America LLC (formerly Freightliner LLC)" 24 "Ford Motor Co., Vehicle Controls" 23 "Ford Motor Co., Heavy Truck" 22 "Ford Motor Co., Electronic Concepts & Systems" 21 "Echlin Inc., Midland Brake Inc." 20 "Eaton Ltd" 19 "Eaton Corp. Trucking Info Services" 18 "Eaton Corp, Transmission Div." 17 "Eaton Corp, Corp Res & Dev" 16 "Eaton Corp" 15 "DICKEY-john Corporation" 14 "Detroit Diesel Corporation" 13 "Delco Electronics" 12 "Deere & Company, Precision Farming" 11 "Dearborn Group Inc." 10 "Cummins Inc (formerly Cummins Engine Co)" 9 "Chrysler Corp." 8 "Caterpillar Inc." 7 "Case Corp." 6 "Berifors Electronics AB" 5 "AMP Inc." 4 "Ametek-Dixson" 3 "Ametek, US Gauge Division" 2 "Allison Transmission, Inc." 1 "Bendix Commercial Vehicle Systems LLC (formerly Allied Signal Inc.)" 0 "Reserved" ;
VAL_ 2559835902 NMControlModeIndicator 0 "Set Pending NAME" 1 "Pending NAME Response" 2 "Current NAME Response" 3 "Set Pending NAME ACK" 4 "Set Pending NAME NACK" 5 "Request Pending Name" 6 "Request Current Name" 7 "Adopt Pending Name" 8 "Request Address Claim" 9 "Reserved for future SAE use" 10 "Reserved for future SAE use" 11 "Reserved for future SAE use" 12 "Reserved for future SAE use" 13 "Reserved for future SAE use" 14 "Reserved for future SAE use" 15 "Reserved for future SAE use" ;
VAL_ 2566786302 VehicleSystem5 127 "Not Available" 0 "Ind. Process Control Stationary" ;
VAL_ 2566786302 VehicleSystem4 125 "Entertainment" 120 "Display" 85 "External Environment" 75 "Sensor Communication Interface" 35 "Electrical Generation" 100 "Deck, Cargo and Fishing Equipment" 90 "Internal Environment" 80 "Instrumentation/General Systems (deprecate)" 70 "Communications" 60 "Navigation" 50 "Propulsion" 40 "Steering and Control Surfaces" 30 "Electrical Distribution" 25 "Inter/Intranetwork Device" 20 "Safety Systems" 10 "System Tools" 127 "Not Available" 0 "Non-specific System" ;
VAL_ 2566786302 VehicleSystem3 8 "Grader" 7 "Four Wheel Drive Loader" 6 "Forklift" 5 "Excavator" 4 "Crawler" 3 "Backhoe" 2 "Articulated Dump Truck" 1 "Skid Steer Loader" 127 "Not Available" 0 "Non-specific System" ;
VAL_ 2566786302 VehicleSystem2 25 "Slurry Applicators" 24 "Utility Vehicles" 23 "Mulchers" 22 "Timber Processing Machines" 21 "Timber loaders" 20 "Forwarders" 19 "Timber Harvesters" 17 "Sensor Systems" 16 "Skidder" 15 "Earth Work" 14 "Special Crops" 13 "Powered Auxiliary Device" 12 "Farm Yard Operations" 11 "Transport/Trailer" 10 "Irrigation" 9 "Forage" 8 "Root Harvesters" 7 "Harvesters" 6 "Sprayers" 5 "Fertilizers" 4 "Planters/Seeders" 3 "Secondary Tillage" 2 "Tillage" 1 "Tractor" 127 "Not Available" 0 "Non-specific System" ;
VAL_ 2566786302 VehicleSystem1 2 "Trailer" 1 "Tractor" 127 "Not Available" 0 "Non-specific System" ;
VAL_ 2566786302 IndustryGroup 6 "Reserved for SAE" 7 "Reserved for SAE" 5 "IndustrialProcessCtrlStationary" 4 "Marine" 3 "Construction" 2 "Agricultural and Forestry" 1 "On-Highway" 0 "Global" ;
VAL_ 2566786302 VehicleSystem 0 "Non-specific System" 127 "Not Available" ;
VAL_ 2566786302 Function 127 "Reserved" 126 "Reserved" 125 "Reserved" 124 "Reserved" 123 "Reserved" 122 "Reserved" 121 "Reserved" 120 "Reserved" 119 "Reserved" 118 "Reserved" 117 "Reserved" 116 "Reserved" 115 "Reserved" 114 "Reserved" 113 "Reserved" 112 "Reserved" 111 "Reserved" 110 "Reserved" 109 "Reserved" 108 "Reserved" 107 "Reserved" 106 "Reserved" 105 "Reserved" 104 "Reserved" 103 "Reserved" 102 "Reserved" 101 "Reserved" 42 "Water Pump Control" 41 "Lighting - Operator Controls" 40 "Seat Control" 39 "Ignition Control Module" 38 "Tire Pressure Control" 37 "Cab Controller" 36 "Pneumatic - System Controller" 35 "Suspension - System Controller" 34 "Hydraulic Pump Controller" 33 "System Monitor" 32 "Headway Controller" 31 "Propulsion Battery Charger" 30 "Management Computer" 29 "Virtual Terminal (in cab)" 28 "Off Vehicle Gateway" 27 "Power TakeOff (Secondary or Front)" 26 "Body Controller" 25 "Network Interconnect ECU" 24 "Vehicle Security" 23 "Vehicle Navigation" 22 "Aerodynamic Control" 21 "Cab Climate Control" 20 "Trip Recorder" 19 "Instrument Cluster" 18 "Suspension - Drive Axle" 17 "Suspension - Steer Axle" 16 "Steering Controller" 15 "Fuel System" 14 "Cruise Control" 13 "Retarder - Driveline" 12 "Retarder - Engine" 11 "Brakes - Drive Axle" 10 "Brakes - Steer Axle" 9 "Brakes - System Controller" 8 "Axle - Drive" 7 "Axle - Steering" 6 "Power TakeOff - (Main or Rear)" 5 "Shift Control/Console" 4 "Battery Pack Monitor" 3 "Transmission" 2 "Electric Propulsion Control" 1 "Auxiliary Power Unit (APU)" 0 "Engine" 100 "Reserved" 99 "Reserved" 98 "Reserved" 97 "Reserved" 96 "Reserved" 95 "Reserved" 94 "Reserved" 93 "Reserved" 92 "Reserved" 91 "Reserved" 90 "Reserved" 89 "Reserved" 88 "Reserved" 87 "Reserved" 86 "Reserved" 85 "Reserved" 84 "Reserved" 83 "Reserved" 82 "Reserved" 81 "Reserved" 80 "Reserved" 79 "Reserved" 78 "Fire Suppression System" 77 "Fuel Properties Sensor" 76 "Temperature Sensor" 75 "Supplemental Fan" 74 "Lubrication System" 73 "Rollover Detection Control" 72 "Coolant Valve Controller" 71 "Transfer Case Control" 70 "Auxiliary Regeneration Device" 69 "Engine Emission Aftertreatement System" 68 "Aftertreatment system gas measurement" 67 "Electrical System Controller" 66 "I/O Controller" 65 "Gas Flow Measurement" 64 "Endurance Braking" 63 "Engine Valve Controller" 62 "On-Board Diagnostic Unit" 61 "File Server/Printer" 60 "Cab Display" 59 "Starter" 58 "Fan Drive Control" 57 "Steering Column Unit" 56 "Communications Unit, Radio" 55 "Communications Unit, Satellite" 54 "Communications Unit, Cellular" 53 "Alternator/Charging System" 52 "Chassis Controller" 51 "Forward-Looking Collision Warning System" 50 "Auxiliary Heater" 49 "Clutch/Converter Control" 48 "Ramp Control" 47 "Information System Controller" 46 "Oil Sensor Unit" 45 "Vehicle Dynamic Stability Control" 44 "Exhaust Emission Control" 43 "Transmission Display" ;
VAL_ 2566786302 ManufacturerCode 1863 "Thomas G. Faria Co." 1862 "Sanshin" 1861 "Vector North America (formerly Vector Cantech)" 1860 "MMP" 1859 "Kvasar AB" 1858 "Litton" 1857 "Simrad" 1856 "Trimble" 1855 "Furuno USA" 1854 "Northstar Technologies" 1853 "Japan Radio Co" 1852 "Navionics" 1851 "RayMarine" 1850 "Seastar Solutions (formerly Teleflex)" 1569 "621 Technologies Inc." 1164 "SEG Automotive" 1163 "DFX Technologies LLC" 1162 "PEL-tuote Oy" 1161 "Griessbach GmbH" 1160 "MG Energy Systems B.V." 1159 "Bel Power Solutions" 1158 "Technoton Electronics" 1157 "Carriergistics" 1156 "Nokian Tyres" 1155 "LACOS Computerservice GmbH" 1154 "TBS Electronics BV" 1153 "Kawasaki Heavy Industries, Ltd." 1152 "Vredo Dodewaard B.V." 1151 "Orca Technologies AS" 1150 "BSB Artificial Intelligence GmbH" 1149 "Wuxi Shengbang Electronics Co., Ltd" 1148 "Stercom Power Solutions GmbH" 1147 "Dana Inc." 1146 "Rometron" 1145 "Kiwi Yachting" 1144 "Troo Corporation" 1143 "Elektro-Szoft 2000" 1142 "Truma" 1141 "MRS Electronic GmbH & Co. KG" 1140 "Across Oceans Systems Ltd." 1139 "ASP Technology" 1138 "Micro-Sensor GmbH" 1137 "SIKO GmbH" 1136 "Primosensor GmbH" 1135 "Japan Aviation Electronics Industry, Limited" 1134 "Master Schools at Ostbahnhof" 1133 "MEGATRON Elektronik GmbH & Co. KG" 1132 "Tokachi Zaidan" 1131 "Guliwer electronics s.r.o." 1130 "Vitesco Technologies" 1129 "Spectrolytic GmbH" 1128 "Citoon Electronic Technology (Tianjin) Co., Ltd." 1127 "ElectroMaax" 1126 "Auralix" 1125 "Griffith-Elder & Co. Ltd." 1124 "Fortron Agriculture" 1123 "QP Hydraulics" 907 "strautmann" 906 "MOBA AG" 905 "ASA Electronics" 904 "Equipment Safety Systems Pty. Ltd. (EQSS)" 903 "InMotion" 902 "Bucher Hydraulics" 901 "Zivan Srl" 900 "OSB AG" 899 "Lippert Components, Inc" 898 "Josef Kotte Landtechnik GmbH & Co. KG" 897 "Dot Technology Corp." 896 "NextFour Solutions Ltd" 895 "Peloton Technology" 894 "Rhodan Marine Systems of Florida LLC" 893 "KlinkTechnics Ltd." 892 "Mectronx Corp" 891 "CarrierWeb" 890 "L3 Technologies, Inc." 889 "SANY America Inc" 888 "Carma Systems Inc" 887 "Hyperdrive Innovation Limited" 886 "Hitachi Zosen Corporation" 885 "SICK Stegmann GmbH" 884 "Sure Grip Controls Inc." 883 "Swift Navigation, Inc." 882 "BHTronik GmbH & Co. KG" 881 "Sovema" 880 "Revision Military" 879 "PG Trionic, Inc." 878 "FOTON" 877 "SICK ATech GmbH" 876 "SUCO Robert Scheuffele GmbH & Co. KG" 875 "Salvarani S.r.l." 874 "MTA S.p.A." 873 "Garnet Instruments Ltd." 872 "Kählig Antriebstechnik GmbH" 871 "Superior Tech Inc" 870 "Textron Fleet Management" 869 "Intercomp" 868 "Data Panel Corp" 867 "Skeleton Technologies" 866 "Netradyne, Inc." 865 "MyEasyFarm" 864 "Streamline Transportation Technologies Inc." 863 "SMAG" 862 "Prospec Electronics" 861 "Adel System S.r.l." 860 "Michelin" 859 "Valor" 858 "Littelfuse" 857 "Zoomlion Heavy Industry NA, Inc" 856 "FarmFacts GmbH" 855 "Toshiba Infrastructure Systems & Solutions Corporation" 1122 "GT Inc." 1121 "Platform Science" 1120 "Elettromedia s.r.l." 1119 "Balmar LLC" 1118 "L3Harris ASV" 1117 "LG Chem, Ltd" 1116 "HR Agrartechnik GmbH" 1115 "Gems Sensors & Controls" 1114 "Bob's Machine" 1113 "iVolve Pty Ltd" 1112 "Bollinger Motors" 1111 "SEPPI M." 1110 "Analytic Systems Ware (1993) Ltd." 1109 "Dockmate" 1108 "ORBCOMM" 1107 "Dräger Safety" 1106 "Great Dane LLC" 1105 "Redekop Manufacturing" 1104 "The Toro Company" 1103 "Diesel Laptops" 1102 "Carl Geringhoff GmbH & Co. KG" 1101 "DIS Sensors B.V." 1100 "Smart Yachts International Limited" 1099 "MadgeTech, Inc" 1098 "Preh GmbH" 1097 "M2M Craft Co., Ltd" 1096 "Texense Sensors" 1095 "WEG Drives and Controls - Automação Ltda" 1094 "Tokushu Denki" 1093 "innolectric" 1092 "Scheiber" 1091 "Wheel Monitor Inc." 1090 "E-T-A Circuit Breakers Ltd" 1089 "Carrosserie HESS AG" 1088 "E-T-A Circuit Breakers" 1087 "ITPhotonics S.r.l." 1086 "Life Racing Ltd" 1085 "Wet Sounds, LLC" 1084 "Shadow-Caster LED lighting LLC" 1083 "Nauticoncept" 1082 "TÜMOSAN Engine and Tractor Co." 1081 "Imcon Electronics, s.r.o." 1080 "Epsilor-Electric Fuel Ltd." 1079 "Carl Zeiss Spectroscopy GmbH" 1078 "GE Appliances" 1077 "Ymer Technology" 1076 "DOGA S.A." 1075 "Uniden America Corporation" 1074 "Kindhelm / Navigs Oy" 1073 "Manitou Equipment America LLC" 1072 "La Marche Manufacturing Company" 1071 "MACH SYSTEMS s.r.o." 1070 "Quick-teck Electronics Ltd" 1069 "Lithionics Battery LLC" 1068 "Zapi S.p.A." 1067 "Tecomec S.r.l." 1066 "Spot Zero Water" 1065 "CALYPSO Instruments" 1064 "Omnitech Robotics Inc." 1063 "SolSteer" 1062 "Marol Co Ltd" 1061 "Volvo Construction Equipment" 1060 "Scale-Tec" 1059 "Boatrax" 1058 "Bondioli & Pavesi SpA" 1057 "EquipmentShare" 1056 "Lithium Pros" 1055 "EXA Computing GmbH" 1054 "Schmotzer Hacktechnik GmbH & Co. KG" 1053 "Vetus Maxwell, Inc." 1052 "Pfreundt" 1051 "ProNav AS" 1050 "Spacenus GmbH" 1049 "S&S Cycle" 1048 "Agrivation UG" 1047 "Sonic Corporation" 1046 "Praxidyn" 1045 "CMR Group" 1044 "Xee" 1043 "Hyva" 1042 "engcon group" 1041 "EZ Lynk" 1040 "BPE Electronics Srl" 1039 "Liugong Dressta Machinery" 1038 "EMIT Technologies, Inc." 1037 "Dragonfly Energy Corp." 1036 "Bender GmbH & Co. KG" 1035 "Agres" 1034 "Siren Marine" 1033 "ECCO Safety Group" 1032 "SIMOL S.p.A." 1031 "Flintec UK Ltd." 1030 "Tume-Agri Oy" 1029 "The Marine Guardian LLC" 1028 "Autel Intelligent Technology Corp., Ltd" 1027 "Goldacres PTY LTD" 1026 "ZTR Control Systems, LLC" 1025 "eze System, Inc." 1024 "Inventus Power" 1023 "PEAK-System Technik GmbH" 1022 "ITC Inc" 1021 "Entratech Systems LLC" 1020 "Onyx Marine Automation s.r.l." 1019 "Codek Foundries" 1018 "Flex TTS" 1017 "Caldaro AB" 1016 "Röhren- und Pumpenwerk BAUER GmbH" 1015 "SECURITAG SAS" 1014 "Briri Maschinenbau GmbH" 1013 "Allochis E-Tec" 1012 "Rhodan Marine Systems of Florida LLC" 1011 "Soundmax Electronics Ltd" 1010 "Agricultural Industry Electronics Foundation e.V." 1009 "TouchTronics, Inc." 1008 "Lintest Systems LLC" 1007 "Maschinenfabrik Meyer-Lohne GmbH" 1006 "Proterra" 1005 "TSE Brakes, Inc." 1004 "Ultraflex SpA" 1003 "technotrans SE" 1002 "Kussmaul Electronics Co." 1001 "Cleral Inc." 1000 "Landmaschinen Wienhoff GmbH" 999 "TerraTroniq B.V." 998 "Transcell Technology Inc" 997 "Xenta Systems Srl" 996 "Eniquest Pty Ltd" 995 "Circuitlink Pty Ltd." 994 "Morris Industries Ltd." 993 "Alelion Energy Systems AB" 992 "MarineIOT LLC" 991 "Deutronic Elektronik GmbH" 990 "SAMSUNG SDI Co., Ltd." 989 "Flux-Geräte GmbH" 988 "Voith Turbo" 987 "Baltic Car Equipment" 986 "AAMP Global" 985 "NLR, LLC" 984 "E-T-A Elektrotechnische Apparate GmbH" 983 "Dezwaef NV" 982 "Briggs & Stratton Corporation" 981 "Kobelt Manufacturing Co. Ltd" 980 "Gussi Italia S.R.L." 979 "McHale" 978 "Canfield Connector" 977 "Emerson Electric Co." 976 "Derive Systems, Inc." 975 "Siemens AG" 974 "Pico Technology Limited" 973 "Zasso GmbH" 972 "Axion AG" 971 "B+B Smartworx" 970 "Jaboni Power Products, LLC" 969 "Blue Sea Systems" 968 "Cox Powertrain Limited" 967 "Moteck Electric Corp." 966 "VisibleFarm" 965 "Ro-Sys Software" 964 "AgroVIR Kft" 963 "Thomason Jones Company, LLC" 962 "Timbolier Industries, Inc." 961 "POK SAS" 960 "Vemcon GmbH" 959 "Cascade Corporation" 958 "NHK MEC Corporation" 957 "Sierra Wireless Inc" 956 "Piher Sensors & Controls S.A." 955 "Hottinger Baldwin (Suzhou) Electronic Measurement Technology Co., Ltd." 954 "Setec Pty Ltd" 953 "Curtiss-Wright" 952 "Tan Delta Systems Ltd" 951 "Exor International S.p.A." 950 "RE:Lab s.r.l." 949 "Škoda Electric a.s." 948 "Donix" 947 "Gerd Bär GmbH" 946 "Hydac Tecnologia Ltda" 945 "Equalizer AG" 944 "ZONTISA Marine SL" 943 "FISCHER AG Präzisionspindeln" 942 "Vogelsang GmbH & Co. KG" 941 "Navya" 940 "Dometal Oy" 939 "Warn Industries, Inc." 938 "LEVEL Systems" 937 "Precision Circuits Inc" 936 "Hi-tech Millennium" 935 "Meels GmbH & Co. KG" 934 "Farmobile, Inc." 933 "Delta Mobile Systems, Inc." 932 "Discover Battery" 931 "Enertec Marine Ltd" 930 "Ecotronix Corp." 929 "Jl Marine Systems, Inc." 928 "EAO Automotive GmbH & Co. KG" 927 "Saicon" 926 "Buhler Industries Inc." 925 "GW Lisk Company" 924 "PAS Peschak Autonome Systeme GmbH" 923 "ELTEK S.p.A." 922 "Terberg Benschop B.V." 921 "ROPA Fahrzeug- und Maschinenbau GmbH" 920 "MTD Consumer Group Inc." 919 "Furrion LLC" 918 "AMW Machine Control, Inc" 917 "Sentinel d.o.o." 916 "Turck Inc." 915 "Dosificacion y sistemas electronicos S.L. (DSE)" 914 "ZETOR TRACTORS a.s." 913 "Toyota Motor Corporation" 912 "Steyr Motors GmbH" 911 "Nautic-On" 910 "Hermann Paus Maschinenfabrik GmbH" 909 "Marines Co., Ltd." 908 "Chonbuk National University Department of Electronics" 854 "GEMAC Chemnitz GmbH" 853 "Teledyne RESON B.V." 852 "Velvac Inc" 851 "Novotechnik Messwertaufnehmer OHG" 850 "Geoprospectors GmbH" 849 "MTS Maschinentechnik Schrode AG" 848 "ningupex" 847 "Oceanvolt" 846 "L3 Magnet-Motor" 845 "GMB Güstrower Maschinenbau GmbH" 844 "FELL AS" 843 "Hendrickson Truck Commercial Vehicle Systems" 842 "DigiDevice Srl" 841 "Agra-GPS" 840 "E.S.T.E. Srl" 839 "Indexator Rotator Systems AB" 838 "Teamsurv Ltd" 837 "Famic Technologies Inc." 836 "Signature4" 835 "PetTrack Ltd." 834 "Pioneer Microsystems, Inc." 833 "Electrum Automation AB" 832 "Heizomat Gerätebau-Energiesysteme GmbH" 831 "DOK-ING Ltd." 830 "Ultra Motion LLC" 829 "Drov Technologies, Inc." 828 "AgriBrink Inc." 827 "INmatix Technology Group Ltd" 826 "Lewmar Marine Inc" 825 "BPW Hungária" 824 "Undheim Systems AS" 823 "ACEINNA, Inc (formerly MEMSIC, Inc)" 822 "Bren-Tronics, Inc." 821 "Thorsen Teknik A/S" 820 "DIaLOGIKa Gesellschaft fuer angewandte Informatik mbH" 819 "Preco Electronics" 818 "HGNSS" 817 "TE Connectivity Sensor Solutions" 816 "UniStrong" 815 "FLIR Systems, Inc." 814 "Kronotech Srl (formerly Soltec Soluzioni Tecnologiche Srl)" 813 "Thales Suisse SA" 812 "Torch Technologies" 811 "Blue Water Desalination" 810 "Dutch Power Company" 809 "HMS Industrial Networks AB" 808 "RIMEX Supply Ltd." 807 "Schneider-Electric" 806 "Charge Automotive Ltd" 805 "Gundersen & Løken AS" 804 "ASA Electronics" 803 "Gill Sensors & Controls Limited" 802 "SPBI (Bj Technologie)" 801 "LOR Manufacturing Company Inc." 800 "Delta-Q Technologies" 799 "Stillwater Designs and Audio, Inc. - KICKER" 798 "Lumishore Ltd" 797 "Tides Marine" 796 "Canadian Automotive Industries Ltd" 795 "Broyda Enterprises Pty Ltd" 794 "Shihlin Electric & Engineering Corporation" 793 "James Fisher Prolec" 792 "Kostal Mexicana" 791 "AUTEC" 790 "VACALL" 789 "GRADALL" 788 "MoTeC Pty Ltd" 787 "Abertax Technologies Limited" 786 "Johnson Matthey Battery Systems" 785 "Fischer Panda GmbH" 784 "CM Automotive Systems, Inc." 783 "Loup Electronics Inc." 782 "AVR bv (formerly AVR bvba)" 781 "Poly-Planar LLC" 780 "AVID Technology Ltd" 779 "RLC Electronic Systems" 778 "Seakeeper Inc." 777 "Ocean Signal Ltd" 776 "HMI Systems LLC" 775 "ZIEHL-ABEGG Automotive GmbH" 774 "Taisho Corporation" 773 "Clarion Corporation of America" 772 "Blink Marine" 771 "Shaw Development, LLC" 770 "MONOSEM" 769 "Trombetta" 768 "Flores Automation, LLC" 767 "Alliance Wireless Technologies Inc." 766 "Epec Oy" 765 "GIGAVAC" 764 "Bednar FMT s.r.o." 763 "AT-Systems BVBA" 762 "ROJ s.r.l." 761 "MITA OLEODINAMICA S.p.A." 760 "Bernecker + Rainer Industrie Elektronik GmbH" 759 "Hydro-Gear" 758 "Banner Engineering Corp." 757 "IMPCO Technologies" 756 "Maschio Gaspardo S.P.A." 755 "Firefly Integrations" 754 "Parker Hannifin Corp., Automation Group" 753 "AIROD Technologies" 752 "Deep Sea Electronics Plc" 751 "Pacific Track" 750 "Joskin SA" 749 "Chart Inc." 748 "IFRA SRL - ISOTTA" 747 "Agratronix" 746 "SureFire Ag Systems, Inc." 745 "Cidra Corporate Services Inc." 744 "Woosung Engineering Co., Ltd." 743 "Daemyung Elevator Co., Ltd." 742 "EROAD" 741 "Carling Technologies" 740 "e-Traction" 739 "LXNAV d.o.o." 738 "Blue Ink Technologies" 737 "Balluff GmbH" 736 "Terex Aerial Work Platforms - Genie" 735 "AEM Performance Electronics" 734 "REAPsystems" 733 "Geotab Inc. (formerly Intendia S.L.)" 732 "Gefran S.p.A." 731 "Modine Manufacturing Company" 730 "BERTHOUD AGRICOLE" 729 "Liebherr" 728 "Streumaster (formerly Streumaster / Panien)" 727 "Dhoot Transmission Pvt Ltd." 726 "MIDORI PRECISIONS" 725 "Hitachi Construction Machinery Co., Ltd." 724 "Electronic Applications, Inc." 723 "Jabil Inc." 722 "Contelec AG" 721 "Hypro" 720 "WITZ Corporation" 719 "Cojali S. L." 718 "Micronet Inc" 717 "Yacht Devices Ltd" 716 "Eaton Control & Power Conversion Division (CPCD)" 715 "Autonnic Research Ltd" 714 "Kobashi Kogyo Co., Ltd." 713 "US Hybrid Corporation" 712 "LOR Manufacturing Company Inc." 711 "DAS Co., LTD" 710 "Greentronics Ltd." 709 "Marquardt GmbH" 708 "Lars Thrane A/S" 707 "Rochester Gauges Inc" 706 "Shanghai Diesel Engine Corporation Limited" 705 "SVAB Hydraulik AB" 704 "JL Audio, Inc." 703 "Hydro Tab Marine Engineering" 702 "Weichai Power Co., Ltd." 701 "BigRoad Inc." 653 "AEV, spol. s r. o." 652 "MicroControl GmbH & Co. KG" 651 "Takakita Co, Ltd." 650 "Seiko Epson Corp." 649 "Control-Q B.V." 648 "OJSC Ekran" 647 "Siloking" 646 "Veenhuis Machines B.V." 645 "esd electronic system design gmbh" 644 "KUS USA" 643 "Bogballe A/S" 642 "Moog / Aspen Motion Technologies" 641 "Diverse Yacht Services" 640 "Power Solutions International" 639 "Startec s.r.l." 638 "KVH Industries, Inc." 637 "Bavaria Yachtbau GmbH" 636 "Divelbiss Corporation" 635 "Argo Tractors S.p.A." 634 "Rocky Research" 633 "TORC Robotics" 632 "Pepperl+Fuchs GmbH" 631 "Reltima" 630 "SmartDrive Systems Inc." 629 "Agri Info Design, Ltd." 628 "Falck Schmidt Defence Systems" 627 "Radio Ocean" 626 "AVL DiTEST GmbH" 625 "Global MRV Inc." 624 "Blackbox Machine Control Pty Ltd" 623 "Xirgo Technologies" 622 "Floyd Bell Inc" 621 "Hagie Manufacturing Company" 620 "Sevcon Ltd." 619 "Right Weigh Load Scales" 618 "Evrard SA" 617 "Zero Emission Vehicles" 616 "SMART-TEC s.r.o." 615 "Networkfleet, Verizon Telematics" 614 "ARLT Technologies GmbH" 613 "HKS Co., Ltd." 612 "Samwon IT" 611 "Esterline" 610 "Trail Tech" 609 "Walvoil S.p.A." 608 "Gale Banks Engineering" 607 "Knappco/Civacon" 606 "Intellian Technologies" 605 "Aventics GmbH" 604 "Rototilt Group AB (formerly Indexator Rototilt Systems AB)" 603 "Kereval" 602 "Nomad Digital Ltd." 601 "Navitas Systems" 600 "Aquatic AV" 142 "TRW Automotive (Commercial Steering Systems)" 141 "Thales Navigation Ltd." 140 "Lowrance Electronics, Inc." 139 "Caterpillar Trimble Control Technologies (CTCT), LLC" 138 "Georg Fritzmeier GmbH & Co. KG" 137 "Maretron" 136 "Komatsu Ltd" 135 "Airmar Technology Corporation" 134 "Iris Technology Ltd" 133 "Bucher Schoerling GmbH" 132 "Mulag-Fahrzeugwerk" 131 "ITT Industries" 130 "Nido - Universal Machines B.V." 129 "OMNEX Control Systems Inc." 128 "Gerhard Duecker GmbH & Co. KG" 127 "Holland USA" 126 "Driver Tech" 125 "Nevada Automotive Test Center" 447 "Great Plains Mfg." 446 "CertTech, L.L.C." 445 "KAT MECHATRONIC, Electronic Product Division" 444 "ITT Power Solutions" 443 "SignalQuest, Inc." 442 "Horsch Maschinen GmbH" 441 "PTG Reifendruckregelsysteme GmbH" 440 "Cummins Power Generation" 439 "Hyundai Heavy Industries" 438 "Comar Systems Ltd" 437 "Digital Yacht Limited" 436 "Kinze Manufacturing" 435 "Zunhammer GmbH" 434 "Stored Energy Systems" 433 "Rowe Electronics" 432 "S&A Systems, Inc." 431 "Tohatsu Corporation" 430 "Auteq Telematica S.A." 429 "Rota Engineering Ltd." 425 "Methode Electronics Inc, MDI" 424 "Odyne LLC" 423 "BSM Wireless, Inc." 422 "True Heading AB" 421 "Vertex Standard Co, Ltd" 420 "Vermeer Corporation, ACS Group" 419 "Fusion Electronics Ltd" 418 "Intellistick Inc" 417 "KZValve" 416 "Kubota Corporation" 415 "Valid Manufacturing Ltd." 414 "Cattron Group International" 413 "Datapross Nijbroek bv" 412 "WebTech Wireless Inc." 411 "Hy-Drive Technologies Ltd." 410 "COBO S.p.A. Divisione 3B6" 409 "Transfluid S.r.L." 408 "Corvus Energy Ltd." 407 "Comtech Mobile Datacom" 406 "Vecima Networks Inc." 405 "Wema System AS" 404 "Com Nav Marine Ltd" 403 "Trackwell ADS, Inc." 402 "Simma Software, Inc." 401 "Torqeedo GmbH" 400 "Livorsi Marine" 399 "ISEKI & Co., Ltd." 398 "Hilite International" 397 "Sanyo-kiki Co Ltd." 396 "Beyond Measure" 395 "GENTEC S.R.L." 394 "Capi 2 Nederland B.V." 393 "Harvest Tec, Inc" 124 "Hydac Electronic" 123 "Basler Electric" 122 "FG Wilson (Engineering) Limited" 121 "HED (Hydro Electronic Devices, Inc.)" 120 "RDS Technology Ltd" 119 "IntegriNautics  " 118 "Intron GmbH" 117 "HUSCO International" 116 "BEELINE Technologies" 115 "NACCO Materials Handling Group, Inc." 114 "EControls, Inc." 113 "Stress-Tek, Inc." 112 "MECALAC" 111 "Bernard Krone Holding SE & Co. KG (formerly Maschinenfabrik Bernard Krone GmbH)" 110 "EPIQ Sensor-Nite" 109 "TeeJet Technologies Denmark (formerly LH Technologies ApS)" 108 "WTK-Elecktronik GmbH" 107 "Grimme Landmaschinen GmbH & Co. KG" 106 "BAE Systems Controls, Inc." 105 "Kiepe Elektrik GmbH & Co. KG" 104 "CLAAS KGaA mbH (formerly CLAAS Selbstfahrende Erntemaschinen GmbH)" 700 "K-Tec Earthmovers Inc." 699 "Harman International Industries" 698 "Scorpion Technologies Ltd." 697 "Ålö AB" 696 "DRS Network & Imaging Systems, LLC (DRS Technologies)" 695 "Weldon Technologies" 694 "GasTOPS Ltd." 693 "Agility Fuel Solutions (formerly Agility Fuel Systems)" 692 "Tanhay Corporation" 691 "Digitroll Agricultural Electronics" 690 "LINAK A/S" 689 "Aarcomm Systems Inc" 688 "Rockford Corp" 687 "Flight Systems, Inc." 686 "Taigene Electric Machinery Corp." 685 "ANEDO (formerly ANEDO Ltd.)" 684 "KEB" 683 "Fosen Elektro" 682 "Eckelmann AG" 681 "BEDIA Motorentechnik GmbH & Co. KG" 680 "AMVAC Chemical Corporation" 679 "OXE Marine AB (formerly Cimco Marine AB)" 678 "KeepTruckin, Inc." 677 "DSA Daten- und Systemtechnik GmbH" 676 "Danfoss IXA A/S" 675 "Kawasaki Motors Corp., USA" 674 "Yara International ASA" 673 "Caruelle Nicolas" 672 "OPTIMA Concept" 671 "Innovative Controls Inc." 670 "STEMCO LP" 669 "Quantum Fuel Systems Technologies Worldwide, Inc" 668 "MacDon Industries Ltd." 667 "Bartec" 666 "Schaeffler Technologies AG & Co., KG" 665 "Gebr. Bode GmbH & Co. KG" 664 "Level Developments Ltd" 663 "Delta Systems, Inc" 662 "Kissling Elektrotechnik GmbH" 661 "SPAL Automotive S.r.l." 660 "Auto-Gaz Centrum" 659 "Data Panel Corp." 658 "Shenzhen Jiuzhou Himunication Technology Co., Ltd" 657 "Terzo Power Systems" 656 "PRO SOLUS do Brasil" 655 "Genge & Thoma AG" 654 "Kohler Power Systems, Detroit Engine Development Center (DEDC)" 599 "Spudnik Equipment Co, LLC" 598 "ABB Turbo Systems Ltd" 597 "Hydac Filter Systems GmbH" 596 "Brunelco Electronic Innovators B.V." 595 "CustomWare" 594 "Kongsberg Automotive" 593 "Sensata Technologies" 592 "tecsis GmbH" 591 "United States Coast Guard" 590 "ARGO-HYTOS GMBH" 589 "MICO, Inc." 588 "Vignal Systems" 587 "JCA Electronics" 586 "Suzuki Motor Corp" 585 "Industrial Electronic Controls" 584 "CarMedialab GmbH" 583 "Yachtcontrol" 582 "Innovative Software Engineering" 581 "Väderstad - Verken AB" 580 "San Jose Technology, Inc." 579 "KVH Industries, Inc." 578 "advanSea" 577 "Denchi Power Ltd  (formerly ABSL Power Solutions Limited)" 576 "Vectia" 575 "Lytx" 574 "Vishay Precision Group" 573 "Orolia Ltd" 572 "Fasse Valves" 571 "Marinecraft Co., Ltd." 570 "frenzel + berg electronic GmbH & Co. KG" 569 "LORD MicroStrain Sensing Systems" 568 "Makersan Ltd. Co." 567 "Lithiumstart LLC" 566 "Geode Technology, Inc." 565 "Micro-Trak Systems, Inc." 564 "Auto Power Electronic" 563 "LOHR Sistemas Eletronicos LTDA" 562 "Bombardier Transportation GmbH" 561 "b-plus GmbH" 560 "Iowa State University, Agricultural and Biosystems Engineering" 559 "Four Peaks Navigation" 558 "Davis Instruments Corp." 557 "Rockson Automation GmbH" 556 "Doosan Infracore Norway" 555 "Sasaki Corporation" 554 "iris-GmbH infrared & intelligent sensors" 553 "KIB Electronics" 552 "Matsuyama Plow Mfg Co, Ltd" 551 "Wexler CSD Ltd." 550 "SUN-A Corporation" 549 "ROAD Deutschland GmbH" 548 "TM4 Inc." 547 "Thomson Linear LLC" 546 "Maruyama Mfg Co, Inc." 545 "GS Hydraulics" 544 "Au Group Electronics" 543 "BAUER Maschinen GmbH" 542 "Dinamica Generale s.p.a." 541 "Total Fire Systems, Inc." 540 "Dinex A/S" 539 "Mobileview" 538 "Crop Ventures, Inc." 537 "Schrader Electronics Ltd." 536 "SSI Technologies" 535 "MOTORPAL, a.s." 534 "Webasto Thermo & Comfort SE" 533 "Doran Manufacturing, LLC" 532 "Onwa Marine Electronics Co Ltd." 531 "Genge & Thoma AG" 530 "NMEA" 529 "National Instruments Korea" 528 "Hoganas AB, Electric Drive Systems" 527 "GKN Walterscheid GmbH" 526 "LOFA Industries, Inc" 525 "Rust Sales INC" 524 "Vomax Instrumentation Pty. Ltd." 523 "Reggio Emilia Innovazione" 522 "Nebraska Tractor Test Laboratory" 521 "Clever Devices Ltd." 520 "Trapeze" 519 "Peeters Landbouwmachines b.v." 518 "Transas USA Inc." 517 "Noland Engineering" 516 "AVAT Automation GmbH" 515 "GINAF Trucks Nederland B.V." 514 "DISTek Integration, Inc." 513 "Precision Technology (formerly FarmscanAg)" 512 "Inpower LLC" 511 "Burel Production (formerly Sulky)" 510 "Marinesoft Co. Ltd" 509 "MOTORTECH GmbH" 508 "Transtech Innovations" 507 "ISOBUS Test Center" 506 "IHI STAR Machinery Corporation" 505 "Yetter Farm Equipment" 504 "Vesper Marine" 503 "Naviop S.R.L." 502 "Attwood Corporation" 501 "Agrotronix S.A." 500 "Oxbo International Corporation" 499 "LCJ Capteurs" 498 "Innovative Design Solutions, Inc." 497 "SENTRON Sistemas Embarcados" 496 "W. Gessmann GmbH" 495 "HOLMER Maschinenbau GmbH" 494 "Synerject" 493 "Watcheye" 492 "Inergy Automotive Systems" 491 "Penny and Giles Ltd" 490 "QuikQ" 489 "Appareo Systems, LLC" 488 "The Charles Machine Works, Inc." 487 "DSE Test Solutions A/S" 486 "Westport Innovations Inc." 485 "MATT automotive" 484 "Headsight Inc." 483 "Valeo" 482 "Tricon Electronics" 481 "Chetco Digital Instruments" 480 "EnerDel, Inc." 479 "Vapor Bus International" 478 "OceanSat B.V." 477 "OilQuick AB" 476 "Hummingbird Marine Electronics" 475 "GME" 474 "Persen Technologies Inc." 473 "Boss Industries, Inc." 472 "Tenneco Inc." 471 "Sea Cross Marine AB" 470 "SI-TEX Marine Electronics" 469 "RA Consulting GmbH" 468 "Tyco Fire Protection Products" 467 "Lely Industries N.V." 466 "Veethree Electronics and Marine LLC" 465 "Ashcroft Inc" 464 "Leach International Corporation" 463 "PROBOTIQ" 462 "IHI Shibaura Machinery Corporation" 461 "HAWE Hydraulik SE" 460 "San Giorgio S.E.I.N." 459 "Alltek Marine Electronics Corp" 458 "Control Solutions, Inc." 457 "RUSELPROM-ElectricDrive Ltd" 456 "General Kinetics" 455 "ADZ NAGANO GmbH" 454 "NGK Spark Plug Co. Ltd" 453 "Cooper Bussmann" 452 "WIKA Alexander Wiegand SE & Co. KG" 451 "Parker Hannifin Corp" 450 "Dycor Technologies Ltd." 449 "Polaris Industries Inc" 448 "Stanadyne Corporation, Electronics Systems" 392 "Tianyuan Technology Co Ltd." 391 "Electronic Design for Industry, Inc" 390 "Partech Inc." 389 "Benchmark Electronics, Minnesota Division" 388 "Innomatix, LLC" 387 "Orscheln Products, LLC" 386 "JLG Automation BVBA" 385 "Johnson Outdoor Marine Electronics" 384 "Camano Light" 383 "MCL Industries" 382 "National Agriculture and Food Research Organization" 381 "B & G" 380 "Suntech International Ltd." 379 "Yamabiko Corporation" 378 "Glendinning Marine Products" 377 "ifm electronic gmbh" 376 "Quake Global" 375 "Williams Controls Inc." 374 "Northern Lights, Inc." 373 "Electronic Design Inc." 372 "Delphi" 371 "Heinzmann GmbH & Co. KG" 370 "Rolls-Royce Marine AS" 369 "Power Torque Engineering Ltd" 368 "HANSENHOF_electronic" 367 "Fliegl Agrartechnik" 366 "Viewnyx Corp." 365 "Digi-Star, LLC" 364 "OEM Controls Inc." 363 "BEI Duncan" 362 "Poettinger Landtechnik GmbH (formerly Alois Poettinger Maschinenfabrik GmbH)" 361 "InMach" 360 "HJS Emission Technology GmbH & Co KG   (formerly HJS Fahrzeugtechnik GmbH & Co KG)" 359 "Ludwig Bergmann GmbH" 358 "Victron Energy B.V." 357 "Hardi International A/S" 356 "Fischer Panda Generators, Inc" 355 "Mastervolt International B.V." 354 "Junkkari OY" 353 "Hegemon Electronics, Inc." 352 "SAME DEUTZ-FAHR GROUP S.p.A." 351 "Thrane & Thrane" 350 "Noris Marine Systems GmbH & Co KG" 349 "Suonentieto" 348 "Amazonen Werke H. Dreyer" 347 "Honeywell" 346 "Control Solutions" 345 "Korean Maritime University" 344 "Parvus Corporation" 343 "Baumer Group" 342 "THOMAS MAGNETE GmbH" 341 "Boning GmbH & Co" 340 "Continental AG" 339 "Competence Center ISOBUS e.V." 338 "GRAF-SYTECO" 337 "Carraro S.p.A." 336 "APE s.r.o." 335 "Evo Electric Ltd" 334 "Takata-Petri AG" 333 "Hadley Products Corporation" 332 "HWH Corporation" 331 "Horton, Inc." 330 "Kidde Aerospace and Defense" 329 "Deif A/S" 328 "Qwerty Electronik AB" 327 "Sonceboz SA" 326 "Akron Brass Company" 325 "ASM Automation Sensorik Messtechnik GmbH" 324 "Snap-on Diagnostics" 323 "Mobileye Vision Technologies Ltd." 322 "MICHENKA s.r.o." 321 "Ultra Electronics, Electrics" 320 "Miedema Landbouwwerktuigenfabriek B.V." 319 "Cadec Global" 318 "SAT Plan" 317 "Navtronics Bvba" 316 "ITT Flow Control" 315 "Icom Incorporated" 314 "CSM GmbH" 313 "Ilmor Engineering, Inc." 312 "Lectronix, Inc." 311 "Patrick Power Products" 310 "TECNORD srl" 309 "Krauss-Maffei Wegmann GmbH & Co. KG" 308 "Cyntrx" 307 "MAS Technologies" 306 "Sleipner Motor AB" 305 "NovAtel Inc" 304 "EmpirBus AB" 303 "CTS Corporation" 302 "Nissin Kogyo Co., LTD" 301 "Parker Hannifin (UK) Ltd FDE group" 300 "Systron Donner Automotive" 299 "Rauch" 298 "Holley Performance" 297 "Zonar Systems Inc" 296 "micro dynamics GmbH" 295 "BEP Marine" 294 "Grayhill Inc." 293 "Spyder Controls Corp." 292 "IKUSI - Angel Iglesias S.A." 291 "Groeneveld Transport Efficiency BV" 290 "Kuebler GmbH" 289 "Watlow" 288 "Mitsubishi FUSO Truck & Bus Corp." 287 "NTech Industries, Inc" 286 "Coelmo srl" 285 "Sea Recovery Corp" 284 "Mobile Tech Chile" 283 "CWF Hamilton & Co Ltd" 282 "Medallion Instrumentation Systems" 281 "Precision Governors LLC" 280 "Leica Geosystems Pty Ltd" 279 "Geometris LP" 278 "Takata Electronics" 277 "LHP Telematics" 276 "Aqua-Hot Heating Systems" 275 "Navico Egersund AS" 274 "LTW Technology Co., LTD" 273 "Active Research Limited" 272 "Gross Mechanical Laboratories, Inc" 271 "Cole Hersee" 270 "Tennant" 269 "Saft America Inc.,  Space & Defense Division" 268 "Accurate Technologies" 267 "Red Lion Controls, Inc" 266 "International Thermal Research Ltd" 265 "MTS Sensor Technologie GmbH" 264 "Autolync" 263 "IMMI" 262 "HydraForce, Inc" 261 "Red Dot Corporation" 260 "Reichhardt GmbH Steuerungstechnik" 259 "Jetter AG" 258 "ARAG" 257 "Honda Motor Co., Ltd" 256 "Tyco Electronics AMP" 255 "MEAS France" 254 "GE Sensing" 253 "Mobile Control Systems" 252 "Sensor-Technik Wiedemann GmbH" 251 "German Agricultural Society, Test Center (DLG)" 250 "Kuhn Group" 249 "Schaltbau GmbH" 248 "Cooper Standard Automotive Active Systems Group" 247 "ePULSE" 246 "Class 1, Inc" 245 "Capstan Ag Systems, Inc." 244 "Techno-Matic" 243 "eRide, Inc." 242 "Kokusandenki Co. Ltd" 241 "Schneider Automation SAS" 240 "Vanair Mfg" 239 "May & Scofield Ltd" 238 "ZF Friedrichshafen AG" 237 "Agtron Enterprises Inc" 236 "NORAC Systems International Inc" 235 "SailorMade Marine Telemetry - Tetra Technology Ltd." 234 "Mondial electronic GmbH" 233 "Yacht Monitoring Solutions Inc." 232 "TSD Integrated Controls" 231 "Topcon Positioning Systems, Inc." 230 "Saucon Technologies" 229 "Garmin International Inc." 228 "Unused (formerly ZF Marine Electronics)" 227 "Lykketronic A/S" 226 "Monaco Coach Corporation" 225 "SKF" 224 "EMMI Network, S.L." 223 "Vaueo Retarder Co., Ltd." 222 "Generac Power Systems, Inc." 221 "SiE" 220 "Beede Electrical Instrument Company, Inc" 219 "Cat OEM Solutions" 218 "Gits Manufacturing Company" 217 "RM Michaelides Software & Elektronik GmbH" 216 "Paneltronics Inc." 215 "Aetna Engineering/Fireboy-Xintex" 214 "MC elettronica Srl" 213 "CNH Belgium N.V." 212 "Sure Power Industries, Inc" 211 "DNA Group" 210 "Iteris, Inc." 209 "Bell Equip. Co. SA (PTY) LTD" 208 "Drew Technologies, Inc" 207 "Otto Engineering" 206 "port GmbH" 205 "SmarTire Systems Inc" 204 "The Morey Corporation" 203 "MILtronik GmbH" 202 "Curtis Instruments, Inc" 201 "Disenos y Tecnologia S.A." 200 "MGM Brakes" 199 "ACTIA Group (formerly Actia Corp)" 198 "Mystic Valley Communications" 197 "Mechron Power Systems" 196 "LEMKEN GmbH & Co KG" 195 "General Engine Products" 194 "TriMark Corporation" 193 "Jeppesen Marine" 192 "Floscan" 191 "XRS Corporation (formerly XATA Corporation)" 190 "Hella KGaA Hueck & Co" 189 "QUALCOMM" 103 "CLAAS E-Systems GmbH (formerly CLAAS E-Systems KGaA mbH & Co. KG)" 102 "AGCO (formerly AGCO GmbH & Co.)" 101 "Sensoria" 100 "VDO Technik AG" 99 "International Transmissions Ltd (ITL)" 98 "Mueller-Elektronik GmbH & Co" 97 "Ag Leader Technology, Inc." 96 "Mech@tronic IT GmbH" 95 "Pacific Insight Electronics Corp." 94 "CNH Industrial N.V. (formerly CNH Global N.V.)" 93 "Perkins Engines Company Ltd." 92 "Ag-Chem Equipment Co., Inc." 91 "BSG Bodensee Steuergeraete GmbH" 90 "Knorr-Bremse SfN GmbH" 89 "Kverneland Group, Electronics Division" 88 "Hemisphere GPS Inc (formerly Satloc Precision GPS)" 188 "EMP Corp" 187 "Air-Weigh" 186 "Altronic, Inc" 185 "Beede Electrical Instrument Company" 184 "EIA Electronics" 183 "KDS Controls, Inc" 182 "Vehicle Systems Engineering B.V." 181 "Coretronics, Inc." 180 "Smart Power Systems" 179 "TeeJet Technologies Springfield (formerly Midwest Technologies Illinois, LLC)" 178 "Continental Automotive GmbH (formerly Siemens VDO Automotive AG)" 177 "Diagnostic Systems Associates" 176 "Moritz Aerospace" 175 "Veris Technologies, Inc." 174 "AB Volvo Penta" 173 "Ryeso, Inc." 172 "Yanmar Co., Ltd. (formerly Yanmar Marine USA)" 171 "Topcon Electronics GmbH & Co. KG (formerly Wachendorff Elektronik GmbH & Co. KG)" 170 "Computronics Corporation Ltd." 169 "Marlin Technologies Inc." 168 "Xantrex" 167 "JLG Industries Inc" 166 "John Deere Electronic Solutions (formerly Phoenix International)" 165 "CPAC Systems AB" 164 "MTU Friedrichshafen GmbH (formerly DaimlerChrysler Off-Highway)" 163 "BRP Inc." 162 "Axiomatic Technologies" 161 "Offshore Systems (UK) Ltd" 160 "Nido" 159 "NTech Industries Inc" 158 "Firestone Industrial Products Company" 157 "ISSPRO Inc." 156 "ITT Industries - Cannon" 155 "Vetronix Corporation" 154 "Westerbeke Corporation" 153 "Woodward, Industrial Controls Division" 152 "elobau GmbH & Co. KG" 151 "Raven Industries, Inc." 150 "Fleetguard" 149 "Holset" 148 "Blue Water Data, Inc." 147 "Nautibus electronic GmbH" 146 "Maxima Technologies" 145 "MurCal Controls" 144 "Mercury Marine" 143 "W. Gmeiner GmbH & Co." 87 "J.C. Bamford Excavators Ltd (JCB)" 86 "C. E. Niehoff & Company" 85 "Kohler Co" 84 "New Holland UK Limited" 83 "Bendix VORAD Technologies (formerly Eaton VORAD Technologies)" 82 "Bobcat/Ingersoll-Rand (formerly Melroe/Ingersoll-Rand)" 81 "Fire Research Corp." 80 "Twin Disc, Inc." 79 "Daimler Benz AG - Engine Division (PBM)" 78 "Frank W. Murphy Manufacturing, Inc" 77 "Deere Power Systems Group" 76 "unused (formerly Deere & Co, Construction Division)" 75 "Deere & Co, Agricultural Division" 74 "Eaton Axle-Brake Division" 73 "LeTourneau, Inc." 72 "Sisu Corporation" 71 "Vansco Electronics Ltd." 70 "Flex-coil Limited" 69 "Trimble Navigation" 68 "Scania" 67 "John Deere Coffeyville Works (formerly Funk Manufacturing Company)" 66 "John Deere Construction Equipment Division" 65 "MAN Nutzfahrzeuge AG" 64 "Unused (formerly SpectraPrecision Laserplane, then SpectraPhysics)" 63 "ZF Industries Inc." 62 "Wabco" 61 "Volvo Truck Corp." 60 "Volvo Trucks North America Inc." 59 "VES Inc." 58 "SPX Corporation, OTC Div" 57 "Danfoss  (formerly Sauer Sundstrand Co, then Sauer-Danfoss Co)" 56 "SAIC" 55 "Ryder System Inc." 54 "Meritor Wabco" 53 "Continental Automotive Systems US, Inc. (formerly Rockwell Land Transportation)" 52 "Meritor Automotive, Inc. (formerly Rockwell Automotive)" 51 "Robert Bosch GmbH" 50 "Robert Bosch Corp" 49 "RE America Inc." 48 "Pollak Alphabet" 47 "Phillips Semiconductor" 46 "Noregon Systems, Inc  (formerly Parasoft Computing Solutions)" 45 "PACCAR" 44 "Nippondenso Co. Ltd." 43 "International Truck and Engine Corporation - Vehicle Electronics (formerly Navistar Intl Trans Corp.)" 42 "International Truck and Engine Corporation - Engine Electronics  (formerly Navistar Intl Trans Co., Engine Electronics)" 41 "Motorola Inc." 40 "Motorola AIEG Inc." 39 "Microfirm Inc." 38 "Micro Processor Systems Inc." 37 "Mack Trucks Inc." 36 "Lucas Ind." 35 "Kenworth Truck Co." 34 "Kelsey Hayes Co." 33 "John Deere" 32 "Jacobs Vehicle Systems" 31 "J Pollak Corp" 30 "Isuzu Motors Ltd" 29 "Hino Motors Ltd." 28 "Grote Ind. Inc." 27 "GMC" 26 "General Motors Corp, Service Technology Grp" 25 "Daimler Trucks North America LLC (formerly Freightliner LLC)" 24 "Ford Motor Co., Vehicle Controls" 23 "Ford Motor Co., Heavy Truck" 22 "Ford Motor Co., Electronic Concepts & Systems" 21 "Echlin Inc., Midland Brake Inc." 20 "Eaton Ltd" 19 "Eaton Corp. Trucking Info Services" 18 "Eaton Corp, Transmission Div." 17 "Eaton Corp, Corp Res & Dev" 16 "Eaton Corp" 15 "DICKEY-john Corporation" 14 "Detroit Diesel Corporation" 13 "Delco Electronics" 12 "Deere & Company, Precision Farming" 11 "Dearborn Group Inc." 10 "Cummins Inc (formerly Cummins Engine Co)" 9 "Chrysler Corp." 8 "Caterpillar Inc." 7 "Case Corp." 6 "Berifors Electronics AB" 5 "AMP Inc." 4 "Ametek-Dixson" 3 "Ametek, US Gauge Division" 2 "Allison Transmission, Inc." 1 "Bendix Commercial Vehicle Systems LLC (formerly Allied Signal Inc.)" 0 "Reserved" ;

SG_MUL_VAL_ 2559835902 CommandedAAC NMControlModeIndicator 0-3, 8-8;
SG_MUL_VAL_ 2559835902 CommandedIndustryGroup NMControlModeIndicator 0-3, 8-8;
SG_MUL_VAL_ 2559835902 CommandedVehicleSystemInstance NMControlModeIndicator 0-3, 8-8;
SG_MUL_VAL_ 2559835902 CommandedVehicleSystem NMControlModeIndicator 0-3, 8-8;
SG_MUL_VAL_ 2559835902 CommandedFunction NMControlModeIndicator 0-3, 8-8;
SG_MUL_VAL_ 2559835902 CommandedFunctionInstance NMControlModeIndicator 0-3, 8-8;
SG_MUL_VAL_ 2559835902 CommandedECUInstance NMControlModeIndicator 0-3, 8-8;
SG_MUL_VAL_ 2559835902 CommandedManufacturerCode NMControlModeIndicator 0-3, 8-8;
SG_MUL_VAL_ 2559835902 AACQualifierFlag NMControlModeIndicator 0-0, 4-4, 8-8;
SG_MUL_VAL_ 2559835902 IndustryGroupQualifierFlag NMControlModeIndicator 0-0, 4-4, 8-8;
SG_MUL_VAL_ 2559835902 VehicleSystemInstanceQualifFlag NMControlModeIndicator 0-0, 4-4, 8-8;
SG_MUL_VAL_ 2559835902 VehicleSystemQualifierFlag NMControlModeIndicator 0-0, 4-4, 8-8;
SG_MUL_VAL_ 2559835902 FunctionQualifierFlag NMControlModeIndicator 0-0, 4-4, 8-8;
SG_MUL_VAL_ 2559835902 FunctionInstanceQualifierFlag NMControlModeIndicator 0-0, 4-4, 8-8;
SG_MUL_VAL_ 2559835902 ECUInstanceQualifierFlag NMControlModeIndicator 0-0, 4-4, 8-8;
SG_MUL_VAL_ 2559835902 ManufacturerCodeQualifierFlag NMControlModeIndicator 0-0, 4-4, 8-8;
